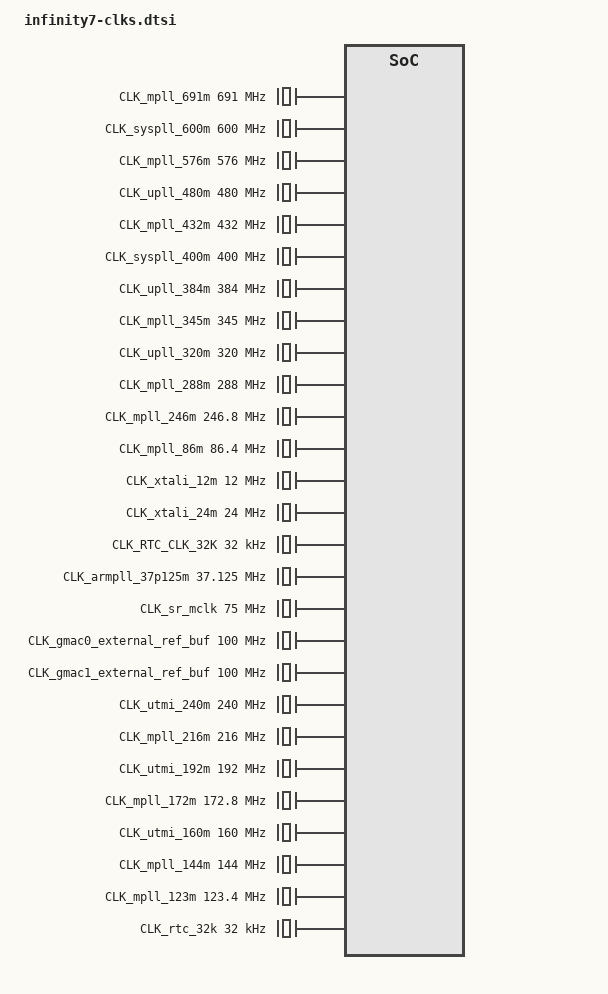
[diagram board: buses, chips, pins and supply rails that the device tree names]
/*
* infinity7-clks.dtsi- Sigmastar
*
* Copyright (c) [2019~2020] SigmaStar Technology.
*
*
* This software is licensed under the terms of the GNU General Public
* License version 2, as published by the Free Software Foundation, and
* may be copied, distributed, and modified under those terms.
*
* This program is distributed in the hope that it will be useful,
* but WITHOUT ANY WARRANTY; without even the implied warranty of
* MERCHANTABILITY or FITNESS FOR A PARTICULAR PURPOSE.  See the
* GNU General Public License version 2 for more details.
*
*/
/* generated by CLK_DT_GEN_5.2 */
/* CLK FILENAME: \\swfs01\Department2\training&Share\infinity7\Doc\04_Phase4\HW\Infinity7_Clock_Table_0214.xls */
/* REG FILENAME: I7\Infinity7_reg_CLKGEN.xls, I7\infinity7_reg_CLKGEN2.xls, I7\infinity7_reg_pm_sleep.xls, I7\Infinity7_reg_block.xls, I7\Infinity7_reg_chiptop.xls */

CLK_VOID: CLK_VOID {
    #clock-cells = <0>;
    compatible = "fixed-clock";
    clock-frequency = <1>;
};

CLK_mpll_691m: CLK_mpll_691m {
    #clock-cells = <0>;
    compatible = "fixed-clock";
    clock-frequency = <691000000>;
};

CLK_syspll_600m: CLK_syspll_600m {
    #clock-cells = <0>;
    compatible = "fixed-clock";
    clock-frequency = <600000000>;
};

CLK_mpll_576m: CLK_mpll_576m {
    #clock-cells = <0>;
    compatible = "fixed-clock";
    clock-frequency = <576000000>;
};

CLK_upll_480m: CLK_upll_480m {
    #clock-cells = <0>;
    compatible = "fixed-clock";
    clock-frequency = <480000000>;
};

CLK_mpll_432m: CLK_mpll_432m {
    #clock-cells = <0>;
    compatible = "fixed-clock";
    clock-frequency = <432000000>;
};

CLK_syspll_400m: CLK_syspll_400m {
    #clock-cells = <0>;
    compatible = "fixed-clock";
    clock-frequency = <400000000>;
};

CLK_upll_384m: CLK_upll_384m {
    #clock-cells = <0>;
    compatible = "fixed-clock";
    clock-frequency = <384000000>;
};

CLK_mpll_345m: CLK_mpll_345m {
    #clock-cells = <0>;
    compatible = "fixed-clock";
    clock-frequency = <345000000>;
};

CLK_upll_320m: CLK_upll_320m {
    #clock-cells = <0>;
    compatible = "fixed-clock";
    clock-frequency = <320000000>;
};

CLK_mpll_288m: CLK_mpll_288m {
    #clock-cells = <0>;
    compatible = "fixed-clock";
    clock-frequency = <288000000>;
};

CLK_mpll_246m: CLK_mpll_246m {
    #clock-cells = <0>;
    compatible = "fixed-clock";
    clock-frequency = <246800000>;
};

CLK_mpll_86m: CLK_mpll_86m {
    #clock-cells = <0>;
    compatible = "fixed-clock";
    clock-frequency = <86400000>;
};

CLK_upll_480m_div2: CLK_upll_480m_div2 {
    #clock-cells = <0>;
    compatible = "fixed-factor-clock";
    clocks = <&CLK_upll_480m>;
    clock-div = <2>;
    clock-mult = <1>;
};

CLK_upll_384m_div2: CLK_upll_384m_div2 {
    #clock-cells = <0>;
    compatible = "fixed-factor-clock";
    clocks = <&CLK_upll_384m>;
    clock-div = <2>;
    clock-mult = <1>;
};

CLK_mpll_345m_div2: CLK_mpll_345m_div2 {
    #clock-cells = <0>;
    compatible = "fixed-factor-clock";
    clocks = <&CLK_mpll_345m>;
    clock-div = <2>;
    clock-mult = <1>;
};

CLK_mpll_288m_div2: CLK_mpll_288m_div2 {
    #clock-cells = <0>;
    compatible = "fixed-factor-clock";
    clocks = <&CLK_mpll_288m>;
    clock-div = <2>;
    clock-mult = <1>;
};

CLK_mpll_288m_div4: CLK_mpll_288m_div4 {
    #clock-cells = <0>;
    compatible = "fixed-factor-clock";
    clocks = <&CLK_mpll_288m>;
    clock-div = <4>;
    clock-mult = <1>;
};

CLK_mpll_288m_div8: CLK_mpll_288m_div8 {
    #clock-cells = <0>;
    compatible = "fixed-factor-clock";
    clocks = <&CLK_mpll_288m>;
    clock-div = <8>;
    clock-mult = <1>;
};

CLK_mpll_432m_div2: CLK_mpll_432m_div2 {
    #clock-cells = <0>;
    compatible = "fixed-factor-clock";
    clocks = <&CLK_mpll_432m>;
    clock-div = <2>;
    clock-mult = <1>;
};

CLK_mpll_432m_div4: CLK_mpll_432m_div4 {
    #clock-cells = <0>;
    compatible = "fixed-factor-clock";
    clocks = <&CLK_mpll_432m>;
    clock-div = <4>;
    clock-mult = <1>;
};

CLK_mpll_432m_div8: CLK_mpll_432m_div8 {
    #clock-cells = <0>;
    compatible = "fixed-factor-clock";
    clocks = <&CLK_mpll_432m>;
    clock-div = <8>;
    clock-mult = <1>;
};

CLK_mpll_432m_div16: CLK_mpll_432m_div16 {
    #clock-cells = <0>;
    compatible = "fixed-factor-clock";
    clocks = <&CLK_mpll_432m>;
    clock-div = <16>;
    clock-mult = <1>;
};

CLK_mpll_246m_div2: CLK_mpll_246m_div2 {
    #clock-cells = <0>;
    compatible = "fixed-factor-clock";
    clocks = <&CLK_mpll_246m>;
    clock-div = <2>;
    clock-mult = <1>;
};

CLK_mpll_246m_div4: CLK_mpll_246m_div4 {
    #clock-cells = <0>;
    compatible = "fixed-factor-clock";
    clocks = <&CLK_mpll_246m>;
    clock-div = <4>;
    clock-mult = <1>;
};

CLK_mpll_86m_div2: CLK_mpll_86m_div2 {
    #clock-cells = <0>;
    compatible = "fixed-factor-clock";
    clocks = <&CLK_mpll_86m>;
    clock-div = <2>;
    clock-mult = <1>;
};

CLK_mpll_86m_div4: CLK_mpll_86m_div4 {
    #clock-cells = <0>;
    compatible = "fixed-factor-clock";
    clocks = <&CLK_mpll_86m>;
    clock-div = <4>;
    clock-mult = <1>;
};

CLK_mpll_86m_div16: CLK_mpll_86m_div16 {
    #clock-cells = <0>;
    compatible = "fixed-factor-clock";
    clocks = <&CLK_mpll_86m>;
    clock-div = <16>;
    clock-mult = <1>;
};

CLK_syspll_400m_div2: CLK_syspll_400m_div2 {
    #clock-cells = <0>;
    compatible = "fixed-factor-clock";
    clocks = <&CLK_syspll_400m>;
    clock-div = <2>;
    clock-mult = <1>;
};

CLK_syspll_400m_div4: CLK_syspll_400m_div4 {
    #clock-cells = <0>;
    compatible = "fixed-factor-clock";
    clocks = <&CLK_syspll_400m>;
    clock-div = <4>;
    clock-mult = <1>;
};

CLK_syspll_400m_div8: CLK_syspll_400m_div8 {
    #clock-cells = <0>;
    compatible = "fixed-factor-clock";
    clocks = <&CLK_syspll_400m>;
    clock-div = <8>;
    clock-mult = <1>;
};

CLK_upll_384m_div8: CLK_upll_384m_div8 {
    #clock-cells = <0>;
    compatible = "fixed-factor-clock";
    clocks = <&CLK_upll_384m>;
    clock-div = <8>;
    clock-mult = <1>;
};

CLK_upll_320m_div2: CLK_upll_320m_div2 {
    #clock-cells = <0>;
    compatible = "fixed-factor-clock";
    clocks = <&CLK_upll_320m>;
    clock-div = <2>;
    clock-mult = <1>;
};

CLK_upll_320m_div8: CLK_upll_320m_div8 {
    #clock-cells = <0>;
    compatible = "fixed-factor-clock";
    clocks = <&CLK_upll_320m>;
    clock-div = <8>;
    clock-mult = <1>;
};

CLK_upll_320m_div10: CLK_upll_320m_div10 {
    #clock-cells = <0>;
    compatible = "fixed-factor-clock";
    clocks = <&CLK_upll_320m>;
    clock-div = <10>;
    clock-mult = <1>;
};

CLK_upll_320m_div16: CLK_upll_320m_div16 {
    #clock-cells = <0>;
    compatible = "fixed-factor-clock";
    clocks = <&CLK_upll_320m>;
    clock-div = <16>;
    clock-mult = <1>;
};

CLK_xtali_12m: CLK_xtali_12m {
    #clock-cells = <0>;
    compatible = "fixed-clock";
    clock-frequency = <12000000>;
};

CLK_xtali_12m_div2: CLK_xtali_12m_div2 {
    #clock-cells = <0>;
    compatible = "fixed-factor-clock";
    clocks = <&CLK_xtali_12m>;
    clock-div = <2>;
    clock-mult = <1>;
};

CLK_xtali_12m_div4: CLK_xtali_12m_div4 {
    #clock-cells = <0>;
    compatible = "fixed-factor-clock";
    clocks = <&CLK_xtali_12m>;
    clock-div = <4>;
    clock-mult = <1>;
};

CLK_xtali_12m_div8: CLK_xtali_12m_div8 {
    #clock-cells = <0>;
    compatible = "fixed-factor-clock";
    clocks = <&CLK_xtali_12m>;
    clock-div = <8>;
    clock-mult = <1>;
};

CLK_xtali_12m_div16: CLK_xtali_12m_div16 {
    #clock-cells = <0>;
    compatible = "fixed-factor-clock";
    clocks = <&CLK_xtali_12m>;
    clock-div = <16>;
    clock-mult = <1>;
};

CLK_xtali_12m_div40: CLK_xtali_12m_div40 {
    #clock-cells = <0>;
    compatible = "fixed-factor-clock";
    clocks = <&CLK_xtali_12m>;
    clock-div = <40>;
    clock-mult = <1>;
};

CLK_xtali_12m_div64: CLK_xtali_12m_div64 {
    #clock-cells = <0>;
    compatible = "fixed-factor-clock";
    clocks = <&CLK_xtali_12m>;
    clock-div = <64>;
    clock-mult = <1>;
};

CLK_xtali_12m_div128: CLK_xtali_12m_div128 {
    #clock-cells = <0>;
    compatible = "fixed-factor-clock";
    clocks = <&CLK_xtali_12m>;
    clock-div = <128>;
    clock-mult = <1>;
};

CLK_xtali_24m: CLK_xtali_24m {
    #clock-cells = <0>;
    compatible = "fixed-clock";
    clock-frequency = <24000000>;
};

CLK_RTC_CLK_32K: CLK_RTC_CLK_32K {
    #clock-cells = <0>;
    compatible = "fixed-clock";
    clock-frequency = <32000>;
};

CLK_pm_riu_w_clk_in: CLK_pm_riu_w_clk_in {
    #clock-cells = <0>;
    compatible = "fixed-clock";
    clock-frequency = <108000000>;
};

CLK_gmacpll_250: CLK_gmacpll_250 {
    #clock-cells = <0>;
    compatible = "fixed-clock";
    clock-frequency = <250000000>;
};

CLK_gmacpll_250_div2: CLK_gmacpll_250_div2 {
    #clock-cells = <0>;
    compatible = "fixed-factor-clock";
    clocks = <&CLK_gmacpll_250>;
    clock-div = <2>;
    clock-mult = <1>;
};

CLK_gmacpll_250_div5: CLK_gmacpll_250_div5 {
    #clock-cells = <0>;
    compatible = "fixed-factor-clock";
    clocks = <&CLK_gmacpll_250>;
    clock-div = <5>;
    clock-mult = <1>;
};

CLK_gmacpll_250_div10: CLK_gmacpll_250_div10 {
    #clock-cells = <0>;
    compatible = "fixed-factor-clock";
    clocks = <&CLK_gmacpll_250>;
    clock-div = <10>;
    clock-mult = <1>;
};

CLK_gmacpll_250_div100: CLK_gmacpll_250_div100 {
    #clock-cells = <0>;
    compatible = "fixed-factor-clock";
    clocks = <&CLK_gmacpll_250>;
    clock-div = <100>;
    clock-mult = <1>;
};

CLK_isppll_clk: CLK_isppll_clk {
    #clock-cells = <0>;
    compatible = "fixed-clock";
    clock-frequency = <600000000>;
};

CLK_isppll_clk_div2: CLK_isppll_clk_div2 {
    #clock-cells = <0>;
    compatible = "fixed-factor-clock";
    clocks = <&CLK_isppll_clk>;
    clock-div = <2>;
    clock-mult = <1>;
};

CLK_isppll_clk_div4: CLK_isppll_clk_div4 {
    #clock-cells = <0>;
    compatible = "fixed-factor-clock";
    clocks = <&CLK_isppll_clk>;
    clock-div = <4>;
    clock-mult = <1>;
};

CLK_isppll_clk_div8: CLK_isppll_clk_div8 {
    #clock-cells = <0>;
    compatible = "fixed-factor-clock";
    clocks = <&CLK_isppll_clk>;
    clock-div = <8>;
    clock-mult = <1>;
};

CLK_isppll_clk_div16: CLK_isppll_clk_div16 {
    #clock-cells = <0>;
    compatible = "fixed-factor-clock";
    clocks = <&CLK_isppll_clk>;
    clock-div = <16>;
    clock-mult = <1>;
};

CLK_syspll_clk: CLK_syspll_clk {
    #clock-cells = <0>;
    compatible = "fixed-clock";
    clock-frequency = <600000000>;
};

CLK_spipll_clk: CLK_spipll_clk {
    #clock-cells = <0>;
    compatible = "fixed-clock";
    clock-frequency = <250000000>;
};

CLK_dsppll_clk: CLK_dsppll_clk {
    #clock-cells = <0>;
    compatible = "fixed-clock";
    clock-frequency = <1000000000>;
};

CLK_utmi: CLK_utmi {
    #clock-cells = <0>;
    compatible = "fixed-clock";
    clock-frequency = <60000000>;
};

CLK_ipupll_clk: CLK_ipupll_clk {
    #clock-cells = <0>;
    compatible = "fixed-clock";
    clock-frequency = <1000000000>;
};

CLK_miupll_clk: CLK_miupll_clk {
    #clock-cells = <0>;
    compatible = "fixed-clock";
    clock-frequency = <533000000>;
};

CLK_ddrpll_clk: CLK_ddrpll_clk {
    #clock-cells = <0>;
    compatible = "fixed-clock";
    clock-frequency = <2133000000>;
};

CLK_lpll_clk: CLK_lpll_clk {
    #clock-cells = <0>;
    compatible = "fixed-clock";
    clock-frequency = <600000000>;
};

CLK_disppll_clk: CLK_disppll_clk {
    #clock-cells = <0>;
    compatible = "fixed-clock";
    clock-frequency = <600000000>;
};

CLK_ven_pll: CLK_ven_pll {
    #clock-cells = <0>;
    compatible = "sstar,complex-clock";
    clocks = <&CLK_xtali_24m>;
};

CLK_ven_pll_div6: CLK_ven_pll_div6 {
    #clock-cells = <0>;
    compatible = "fixed-clock";
    clock-frequency = <100000000>;
};

CLK_cpu_pll: CLK_cpu_pll {
    #clock-cells = <0>;
    compatible = "fixed-clock";
    clock-frequency = <1000000000>;
};

CLK_lpll_clk_div2: CLK_lpll_clk_div2 {
    #clock-cells = <0>;
    compatible = "fixed-factor-clock";
    clocks = <&CLK_lpll_clk>;
    clock-div = <2>;
    clock-mult = <1>;
};

CLK_lpll_clk_div4: CLK_lpll_clk_div4 {
    #clock-cells = <0>;
    compatible = "fixed-factor-clock";
    clocks = <&CLK_lpll_clk>;
    clock-div = <4>;
    clock-mult = <1>;
};

CLK_lpll_clk_div8: CLK_lpll_clk_div8 {
    #clock-cells = <0>;
    compatible = "fixed-factor-clock";
    clocks = <&CLK_lpll_clk>;
    clock-div = <8>;
    clock-mult = <1>;
};

CLK_disppll_clk_div2: CLK_disppll_clk_div2 {
    #clock-cells = <0>;
    compatible = "fixed-factor-clock";
    clocks = <&CLK_disppll_clk>;
    clock-div = <2>;
    clock-mult = <1>;
};

CLK_disppll_clk_div4: CLK_disppll_clk_div4 {
    #clock-cells = <0>;
    compatible = "fixed-factor-clock";
    clocks = <&CLK_disppll_clk>;
    clock-div = <4>;
    clock-mult = <1>;
};

CLK_disppll_clk_div8: CLK_disppll_clk_div8 {
    #clock-cells = <0>;
    compatible = "fixed-factor-clock";
    clocks = <&CLK_disppll_clk>;
    clock-div = <8>;
    clock-mult = <1>;
};

CLK_armpll_37p125m: CLK_armpll_37p125m {
    #clock-cells = <0>;
    compatible = "fixed-clock";
    clock-frequency = <37125000>;
};

CLK_riu_w_clk_in: CLK_riu_w_clk_in {
    #clock-cells = <0>;
    compatible = "fixed-factor-clock";
    clocks = <&CLK_mcu>;
    clock-div = <1>;
    clock-mult = <1>;
};

CLK_riu_w_clk_top: CLK_riu_w_clk_top {
    #clock-cells = <0>;
    compatible = "fixed-factor-clock";
    clocks = <&CLK_mcu>;
    clock-div = <1>;
    clock-mult = <1>;
};

CLK_riu_w_clk_sc_gp: CLK_riu_w_clk_sc_gp {
    #clock-cells = <0>;
    compatible = "fixed-factor-clock";
    clocks = <&CLK_mcu>;
    clock-div = <1>;
    clock-mult = <1>;
};

CLK_riu_w_clk_vhe_gp: CLK_riu_w_clk_vhe_gp {
    #clock-cells = <0>;
    compatible = "fixed-factor-clock";
    clocks = <&CLK_mcu>;
    clock-div = <1>;
    clock-mult = <1>;
};

CLK_riu_w_clk_hemcu_gp: CLK_riu_w_clk_hemcu_gp {
    #clock-cells = <0>;
    compatible = "fixed-factor-clock";
    clocks = <&CLK_mcu>;
    clock-div = <1>;
    clock-mult = <1>;
};

CLK_riu_w_clk_mipi_if_gp: CLK_riu_w_clk_mipi_if_gp {
    #clock-cells = <0>;
    compatible = "fixed-factor-clock";
    clocks = <&CLK_mcu>;
    clock-div = <1>;
    clock-mult = <1>;
};

CLK_riu_w_clk_mcu_if_gp: CLK_riu_w_clk_mcu_if_gp {
    #clock-cells = <0>;
    compatible = "fixed-factor-clock";
    clocks = <&CLK_mcu>;
    clock-div = <1>;
    clock-mult = <1>;
};

CLK_spi_synth_pll: CLK_spi_synth_pll {
    #clock-cells = <0>;
    compatible = "fixed-clock";
    clock-frequency = <104000000>;
};

CLK_fuart0_synth_out: CLK_fuart0_synth_out {
    #clock-cells = <0>;
    compatible = "sstar,complex-clock";
    clocks = <&CLK_fuart0_synth_in>;

};

CLK_miu: CLK_miu {
    #clock-cells = <0>;
    compatible = "fixed-clock";
    clock-frequency = <400000000>;
};

CLK_miu_p: CLK_miu_p {
    #clock-cells = <0>;
    compatible = "fixed-factor-clock";
    clocks = <&CLK_miu>;
    clock-div = <1>;
    clock-mult = <1>;
};

CLK_mspi0_p: CLK_mspi0_p {
    #clock-cells = <0>;
    compatible = "fixed-factor-clock";
    clocks = <&CLK_mspi0>;
    clock-div = <1>;
    clock-mult = <1>;
};

CLK_mspi1_p: CLK_mspi1_p {
    #clock-cells = <0>;
    compatible = "fixed-factor-clock";
    clocks = <&CLK_mspi1>;
    clock-div = <1>;
    clock-mult = <1>;
};

CLK_miu_vhe_gp_p: CLK_miu_vhe_gp_p {
    #clock-cells = <0>;
    compatible = "fixed-factor-clock";
    clocks = <&CLK_miu>;
    clock-div = <1>;
    clock-mult = <1>;
};

CLK_miu_sc_gp_p: CLK_miu_sc_gp_p {
    #clock-cells = <0>;
    compatible = "fixed-factor-clock";
    clocks = <&CLK_miu>;
    clock-div = <1>;
    clock-mult = <1>;
};

CLK_miu_isp_gp_p: CLK_miu_isp_gp_p {
    #clock-cells = <0>;
    compatible = "fixed-factor-clock";
    clocks = <&CLK_miu>;
    clock-div = <1>;
    clock-mult = <1>;
};

CLK_miu2x_p: CLK_miu2x_p {
    #clock-cells = <0>;
    compatible = "fixed-factor-clock";
    clocks = <&CLK_miu>;
    clock-div = <1>;
    clock-mult = <1>;
};

CLK_mcu_p: CLK_mcu_p {
    #clock-cells = <0>;
    compatible = "fixed-factor-clock";
    clocks = <&CLK_mcu>;
    clock-div = <1>;
    clock-mult = <1>;
};

CLK_mcu_pm_p: CLK_mcu_pm_p {
    #clock-cells = <0>;
    compatible = "fixed-factor-clock";
    clocks = <&CLK_mcu_pm>;
    clock-div = <1>;
    clock-mult = <1>;
};

CLK_isp_p: CLK_isp_p {
    #clock-cells = <0>;
    compatible = "fixed-factor-clock";
    clocks = <&CLK_isp>;
    clock-div = <1>;
    clock-mult = <1>;
};

CLK_fclk1_p: CLK_fclk1_p {
    #clock-cells = <0>;
    compatible = "fixed-factor-clock";
    clocks = <&CLK_fclk1>;
    clock-div = <1>;
    clock-mult = <1>;
};

CLK_sdio_p: CLK_sdio_p {
    #clock-cells = <0>;
    compatible = "fixed-factor-clock";
    clocks = <&CLK_sdio>;
    clock-div = <1>;
    clock-mult = <1>;
};

CLK_sd_1x_p: CLK_sd_1x_p {
    #clock-cells = <0>;
    compatible = "fixed-clock";
    clock-frequency = <110000000>;
};

CLK_sd_2x_p: CLK_sd_2x_p {
    #clock-cells = <0>;
    compatible = "fixed-clock";
    clock-frequency = <220000000>;
};

CLK_sr_mclk: CLK_sr_mclk {
    #clock-cells = <0>;
    compatible = "fixed-clock";
    clock-frequency = <75000000>;
};

CLK_tck_buf: CLK_tck_buf {
    #clock-cells = <0>;
    compatible = "fixed-clock";
    clock-frequency = <50000000>;
};

CLK_eth_buf: CLK_eth_buf {
    #clock-cells = <0>;
    compatible = "fixed-clock";
    clock-frequency = <125000000>;
};

CLK_rmii_buf: CLK_rmii_buf {
    #clock-cells = <0>;
    compatible = "fixed-clock";
    clock-frequency = <125000000>;
};

CLK_emac_testrx125_in_lan: CLK_emac_testrx125_in_lan {
    #clock-cells = <0>;
    compatible = "fixed-clock";
    clock-frequency = <125000000>;
};

CLK_gmac0_external_ref_buf: CLK_gmac0_external_ref_buf {
    #clock-cells = <0>;
    compatible = "fixed-clock";
    clock-frequency = <100000000>;
};

CLK_gmac1_external_ref_buf: CLK_gmac1_external_ref_buf {
    #clock-cells = <0>;
    compatible = "fixed-clock";
    clock-frequency = <100000000>;
};

CLK_utmi_240m: CLK_utmi_240m {
    #clock-cells = <0>;
    compatible = "fixed-clock";
    clock-frequency = <240000000>;
};

CLK_mpll_216m: CLK_mpll_216m {
    #clock-cells = <0>;
    compatible = "fixed-clock";
    clock-frequency = <216000000>;
};

CLK_utmi_192m: CLK_utmi_192m {
    #clock-cells = <0>;
    compatible = "fixed-clock";
    clock-frequency = <192000000>;
};

CLK_mpll_172m: CLK_mpll_172m {
    #clock-cells = <0>;
    compatible = "fixed-clock";
    clock-frequency = <172800000>;
};

CLK_utmi_160m: CLK_utmi_160m {
    #clock-cells = <0>;
    compatible = "fixed-clock";
    clock-frequency = <160000000>;
};

CLK_mpll_144m: CLK_mpll_144m {
    #clock-cells = <0>;
    compatible = "fixed-clock";
    clock-frequency = <144000000>;
};

CLK_mpll_123m: CLK_mpll_123m {
    #clock-cells = <0>;
    compatible = "fixed-clock";
    clock-frequency = <123400000>;
};

CLK_mpll_216m_div2: CLK_mpll_216m_div2 {
    #clock-cells = <0>;
    compatible = "fixed-factor-clock";
    clocks = <&CLK_mpll_216m>;
    clock-div = <2>;
    clock-mult = <1>;
};

CLK_mpll_216m_div4: CLK_mpll_216m_div4 {
    #clock-cells = <0>;
    compatible = "fixed-factor-clock";
    clocks = <&CLK_mpll_216m>;
    clock-div = <4>;
    clock-mult = <1>;
};

CLK_mpll_216m_div8: CLK_mpll_216m_div8 {
    #clock-cells = <0>;
    compatible = "fixed-factor-clock";
    clocks = <&CLK_mpll_216m>;
    clock-div = <8>;
    clock-mult = <1>;
};

CLK_mpll_144m_div2: CLK_mpll_144m_div2 {
    #clock-cells = <0>;
    compatible = "fixed-factor-clock";
    clocks = <&CLK_mpll_144m>;
    clock-div = <2>;
    clock-mult = <1>;
};

CLK_mpll_144m_div4: CLK_mpll_144m_div4 {
    #clock-cells = <0>;
    compatible = "fixed-factor-clock";
    clocks = <&CLK_mpll_144m>;
    clock-div = <4>;
    clock-mult = <1>;
};

CLK_mpll_123m_div2: CLK_mpll_123m_div2 {
    #clock-cells = <0>;
    compatible = "fixed-factor-clock";
    clocks = <&CLK_mpll_123m>;
    clock-div = <2>;
    clock-mult = <1>;
};

CLK_utmi_192m_div4: CLK_utmi_192m_div4 {
    #clock-cells = <0>;
    compatible = "fixed-factor-clock";
    clocks = <&CLK_utmi_192m>;
    clock-div = <4>;
    clock-mult = <1>;
};

CLK_utmi_160m_div4: CLK_utmi_160m_div4 {
    #clock-cells = <0>;
    compatible = "fixed-factor-clock";
    clocks = <&CLK_utmi_160m>;
    clock-div = <4>;
    clock-mult = <1>;
};

CLK_utmi_160m_div5: CLK_utmi_160m_div5 {
    #clock-cells = <0>;
    compatible = "fixed-factor-clock";
    clocks = <&CLK_utmi_160m>;
    clock-div = <5>;
    clock-mult = <1>;
};

CLK_utmi_160m_div8: CLK_utmi_160m_div8 {
    #clock-cells = <0>;
    compatible = "fixed-factor-clock";
    clocks = <&CLK_utmi_160m>;
    clock-div = <8>;
    clock-mult = <1>;
};

CLK_xtali_12m_div12: CLK_xtali_12m_div12 {
    #clock-cells = <0>;
    compatible = "fixed-factor-clock";
    clocks = <&CLK_xtali_12m>;
    clock-div = <12>;
    clock-mult = <1>;
};

CLK_rtc_32k: CLK_rtc_32k {
    #clock-cells = <0>;
    compatible = "fixed-clock";
    clock-frequency = <32000>;
};

CLK_rtc_32k_div4: CLK_rtc_32k_div4 {
    #clock-cells = <0>;
    compatible = "fixed-factor-clock";
    clocks = <&CLK_rtc_32k>;
    clock-div = <4>;
    clock-mult = <1>;
};

CLK_cpupll_clk: CLK_cpupll_clk {
    #clock-cells = <0>;
    compatible = "sstar,complex-clock";
    clocks = <&CLK_mpll_432m>;
};

CLK_SPI_SYNTH_CLK_OUT_buf: CLK_SPI_SYNTH_CLK_OUT_buf {
    #clock-cells = <0>;
    compatible = "fixed-clock";
    clock-frequency = <104000000>;
};

CLK_live_pm: CLK_live_pm {
    #clock-cells = <0>;
    compatible = "fixed-factor-clock";
    clocks = <&CLK_xtali_12m>;
    clock-div = <1>;
    clock-mult = <1>;
};

CLK_riu_pm: CLK_riu_pm {
    #clock-cells = <0>;
    compatible = "fixed-factor-clock";
    clocks = <&CLK_pm_riu_w_clk_in>;
    clock-div = <1>;
    clock-mult = <1>;
};

CLK_ddr_syn: CLK_ddr_syn {
    #clock-cells = <0>;
    compatible = "sstar,composite-clock";
    clocks = <&CLK_mpll_432m>,<&CLK_mpll_432m_div2>,<&CLK_xtali_12m>,<&CLK_VOID>;
    reg = <REG_CKG_DDR_SYN_BASE 0x4>;
    mux-shift = <2>;  //2+REG_CKG_DDR_SYN_OFFSET
    mux-width = <2>;
    gate-shift = <0>;  //0+REG_CKG_DDR_SYN_OFFSET
    auto-enable = <1>;
};

CLK_miu_rec: CLK_miu_rec {
    #clock-cells = <0>;
    compatible = "sstar,composite-clock";
    clocks = <&CLK_xtali_12m_div8>,<&CLK_xtali_12m_div16>,<&CLK_xtali_12m_div64>,<&CLK_xtali_12m_div128>;
    reg = <REG_CKG_MIU_REC_BASE 0x4>;
    mux-shift = <2>;  //2+REG_CKG_MIU_REC_OFFSET
    mux-width = <2>;
    gate-shift = <0>;  //0+REG_CKG_MIU_REC_OFFSET
    auto-enable = <1>;
};

CLK_mcu: CLK_mcu {
    #clock-cells = <0>;
    compatible = "sstar,composite-clock";
    clocks = <&CLK_mpll_432m_div2>,<&CLK_mpll_432m>,<&CLK_upll_320m>,<&CLK_mpll_345m>,<&CLK_upll_384m>,<&CLK_mpll_288m>,<&CLK_mpll_345m_div2>,<&CLK_mpll_432m_div4>;
    reg = <REG_CKG_MCU_BASE 0x4>;
    mux-shift = <2>;  //2+REG_CKG_MCU_OFFSET
    mux-width = <3>;
    gate-shift = <0>;  //0+REG_CKG_MCU_OFFSET
    glitch-shift = <5>;  //5+REG_CKG_MCU_OFFSET
    auto-enable = <1>;
};

CLK_riubrdg: CLK_riubrdg {
    #clock-cells = <0>;
    compatible = "sstar,composite-clock";
    clocks = <&CLK_mcu_p>,<&CLK_VOID>,<&CLK_VOID>,<&CLK_VOID>;
    reg = <REG_CKG_RIUBRDG_BASE 0x4>;
    mux-shift = <10>;  //2+REG_CKG_RIUBRDG_OFFSET
    mux-width = <2>;
    gate-shift = <8>;  //0+REG_CKG_RIUBRDG_OFFSET
    auto-enable = <1>;
};

CLK_spi_arb: CLK_spi_arb {
    #clock-cells = <0>;
    compatible = "sstar,composite-clock";
    clocks = <&CLK_miu_p>,<&CLK_VOID>,<&CLK_VOID>,<&CLK_VOID>;
    reg = <REG_CKG_SPI_ARB_BASE 0x4>;
    mux-shift = <2>;  //2+REG_CKG_SPI_ARB_OFFSET
    mux-width = <2>;
    gate-shift = <0>;  //0+REG_CKG_SPI_ARB_OFFSET
    glitch-shift = <4>;  //4+REG_CKG_SPI_ARB_OFFSET
    auto-enable = <0>;
};

CLK_pwm: CLK_pwm {
    #clock-cells = <0>;
    compatible = "sstar,composite-clock";
    clocks = <&CLK_xtali_12m>,<&CLK_xtali_12m_div2>,<&CLK_xtali_12m_div4>,<&CLK_xtali_12m_div8>,<&CLK_xtali_12m_div16>,<&CLK_mpll_86m>,<&CLK_VOID>,<&CLK_VOID>;
    reg = <REG_CKG_PWM_BASE 0x4>;
    mux-shift = <10>;  //2+REG_CKG_PWM_OFFSET
    mux-width = <3>;
    gate-shift = <8>;  //0+REG_CKG_PWM_OFFSET
    auto-enable = <0>;
};

CLK_uart0: CLK_uart0 {
    #clock-cells = <0>;
    compatible = "sstar,composite-clock";
    clocks = <&CLK_mpll_345m_div2>,<&CLK_mpll_288m_div2>,<&CLK_xtali_24m>,<&CLK_xtali_12m>;
    reg = <REG_CKG_UART0_BASE 0x4>;
    mux-shift = <2>;  //2+REG_CKG_UART0_OFFSET
    mux-width = <2>;
    gate-shift = <0>;  //0+REG_CKG_UART0_OFFSET
    auto-enable = <1>;
};

CLK_uart1: CLK_uart1 {
    #clock-cells = <0>;
    compatible = "sstar,composite-clock";
    clocks = <&CLK_mpll_345m_div2>,<&CLK_mpll_288m_div2>,<&CLK_xtali_24m>,<&CLK_xtali_12m>;
    reg = <REG_CKG_UART1_BASE 0x4>;
    mux-shift = <6>;  //2+REG_CKG_UART1_OFFSET
    mux-width = <2>;
    gate-shift = <4>;  //0+REG_CKG_UART1_OFFSET
    auto-enable = <0>;
};

CLK_uart2: CLK_uart2 {
    #clock-cells = <0>;
    compatible = "sstar,composite-clock";
    clocks = <&CLK_mpll_345m_div2>,<&CLK_mpll_288m_div2>,<&CLK_xtali_24m>,<&CLK_xtali_12m>;
    reg = <REG_CKG_UART2_BASE 0x4>;
    mux-shift = <10>;  //2+REG_CKG_UART2_OFFSET
    mux-width = <2>;
    gate-shift = <8>;  //0+REG_CKG_UART2_OFFSET
    auto-enable = <0>;
};

CLK_uart3: CLK_uart3 {
    #clock-cells = <0>;
    compatible = "sstar,composite-clock";
    clocks = <&CLK_mpll_345m_div2>,<&CLK_mpll_288m_div2>,<&CLK_xtali_24m>,<&CLK_xtali_12m>;
    reg = <REG_CKG_UART3_BASE 0x4>;
    mux-shift = <14>;  //2+REG_CKG_UART3_OFFSET
    mux-width = <2>;
    gate-shift = <12>;  //0+REG_CKG_UART3_OFFSET
    auto-enable = <0>;
};

CLK_uart4: CLK_uart4 {
    #clock-cells = <0>;
    compatible = "sstar,composite-clock";
    clocks = <&CLK_mpll_345m_div2>,<&CLK_mpll_288m_div2>,<&CLK_xtali_24m>,<&CLK_xtali_12m>;
    reg = <REG_CKG_UART4_BASE 0x4>;
    mux-shift = <2>;  //2+REG_CKG_UART4_OFFSET
    mux-width = <2>;
    gate-shift = <0>;  //0+REG_CKG_UART4_OFFSET
    auto-enable = <0>;
};

CLK_uart5: CLK_uart5 {
    #clock-cells = <0>;
    compatible = "sstar,composite-clock";
    clocks = <&CLK_mpll_345m_div2>,<&CLK_mpll_288m_div2>,<&CLK_xtali_24m>,<&CLK_xtali_12m>;
    reg = <REG_CKG_UART5_BASE 0x4>;
    mux-shift = <2>;  //2+REG_CKG_UART5_OFFSET
    mux-width = <2>;
    gate-shift = <0>;  //0+REG_CKG_UART5_OFFSET
    auto-enable = <0>;
};

CLK_fuart0_synth_in: CLK_fuart0_synth_in {
    #clock-cells = <0>;
    compatible = "sstar,composite-clock";
    clocks = <&CLK_mpll_432m>,<&CLK_mpll_432m_div2>,<&CLK_VOID>,<&CLK_VOID>;
    reg = <REG_CKG_FUART0_SYNTH_IN_BASE 0x4>;
    mux-shift = <6>;  //2+REG_CKG_FUART0_SYNTH_IN_OFFSET
    mux-width = <2>;
    gate-shift = <4>;  //0+REG_CKG_FUART0_SYNTH_IN_OFFSET
    auto-enable = <0>;
};

CLK_fuart: CLK_fuart {
    #clock-cells = <0>;
    compatible = "sstar,composite-clock";
    clocks = <&CLK_mpll_345m_div2>,<&CLK_mpll_288m_div2>,<&CLK_xtali_12m>,<&CLK_fuart0_synth_out>;
    reg = <REG_CKG_FUART_BASE 0x4>;
    mux-shift = <2>;  //2+REG_CKG_FUART_OFFSET
    mux-width = <2>;
    gate-shift = <0>;  //0+REG_CKG_FUART_OFFSET
    auto-enable = <0>;
};

CLK_mspi0: CLK_mspi0 {
    #clock-cells = <0>;
    compatible = "sstar,composite-clock";
    clocks = <&CLK_mpll_432m_div4>,<&CLK_mpll_432m_div8>,<&CLK_xtali_12m>,<&CLK_mpll_288m_div2>;
    reg = <REG_CKG_MSPI0_BASE 0x4>;
    mux-shift = <2>;  //2+REG_CKG_MSPI0_OFFSET
    mux-width = <2>;
    gate-shift = <0>;  //0+REG_CKG_MSPI0_OFFSET
    auto-enable = <0>;
};

CLK_mspi1: CLK_mspi1 {
    #clock-cells = <0>;
    compatible = "sstar,composite-clock";
    clocks = <&CLK_mpll_432m_div4>,<&CLK_mpll_432m_div8>,<&CLK_xtali_12m>,<&CLK_mpll_288m_div2>;
    reg = <REG_CKG_MSPI1_BASE 0x4>;
    mux-shift = <10>;  //2+REG_CKG_MSPI1_OFFSET
    mux-width = <2>;
    gate-shift = <8>;  //0+REG_CKG_MSPI1_OFFSET
    auto-enable = <0>;
};

CLK_mspi2: CLK_mspi2 {
    #clock-cells = <0>;
    compatible = "sstar,composite-clock";
    clocks = <&CLK_mpll_432m_div4>,<&CLK_mpll_432m_div8>,<&CLK_xtali_12m>,<&CLK_mpll_288m_div2>;
    reg = <REG_CKG_MSPI2_BASE 0x4>;
    mux-shift = <10>;  //2+REG_CKG_MSPI2_OFFSET
    mux-width = <2>;
    gate-shift = <8>;  //0+REG_CKG_MSPI2_OFFSET
    auto-enable = <0>;
};

CLK_mspi3: CLK_mspi3 {
    #clock-cells = <0>;
    compatible = "sstar,composite-clock";
    clocks = <&CLK_mpll_432m_div4>,<&CLK_mpll_432m_div8>,<&CLK_xtali_12m>,<&CLK_mpll_288m_div2>;
    reg = <REG_CKG_MSPI3_BASE 0x4>;
    mux-shift = <14>;  //2+REG_CKG_MSPI3_OFFSET
    mux-width = <2>;
    gate-shift = <12>;  //0+REG_CKG_MSPI3_OFFSET
    auto-enable = <0>;
};

CLK_miic0: CLK_miic0 {
    #clock-cells = <0>;
    compatible = "sstar,composite-clock";
    clocks = <&CLK_mpll_288m_div4>,<&CLK_mpll_432m_div8>,<&CLK_xtali_12m>,<&CLK_VOID>;
    reg = <REG_CKG_MIIC0_BASE 0x4>;
    mux-shift = <2>;  //2+REG_CKG_MIIC0_OFFSET
    mux-width = <2>;
    gate-shift = <0>;  //0+REG_CKG_MIIC0_OFFSET
    auto-enable = <0>;
};

CLK_miic1: CLK_miic1 {
    #clock-cells = <0>;
    compatible = "sstar,composite-clock";
    clocks = <&CLK_mpll_288m_div4>,<&CLK_mpll_432m_div8>,<&CLK_xtali_12m>,<&CLK_VOID>;
    reg = <REG_CKG_MIIC1_BASE 0x4>;
    mux-shift = <10>;  //2+REG_CKG_MIIC1_OFFSET
    mux-width = <2>;
    gate-shift = <8>;  //0+REG_CKG_MIIC1_OFFSET
    auto-enable = <0>;
};

CLK_miic2: CLK_miic2 {
    #clock-cells = <0>;
    compatible = "sstar,composite-clock";
    clocks = <&CLK_mpll_288m_div4>,<&CLK_mpll_432m_div8>,<&CLK_xtali_12m>,<&CLK_VOID>;
    reg = <REG_CKG_MIIC2_BASE 0x4>;
    mux-shift = <14>;  //2+REG_CKG_MIIC2_OFFSET
    mux-width = <2>;
    gate-shift = <12>;  //0+REG_CKG_MIIC2_OFFSET
    auto-enable = <0>;
};

CLK_miic3: CLK_miic3 {
    #clock-cells = <0>;
    compatible = "sstar,composite-clock";
    clocks = <&CLK_mpll_288m_div4>,<&CLK_mpll_432m_div8>,<&CLK_xtali_12m>,<&CLK_VOID>;
    reg = <REG_CKG_MIIC3_BASE 0x4>;
    mux-shift = <2>;  //2+REG_CKG_MIIC3_OFFSET
    mux-width = <2>;
    gate-shift = <0>;  //0+REG_CKG_MIIC3_OFFSET
    auto-enable = <0>;
};

CLK_miic4: CLK_miic4 {
    #clock-cells = <0>;
    compatible = "sstar,composite-clock";
    clocks = <&CLK_mpll_288m_div4>,<&CLK_mpll_432m_div8>,<&CLK_xtali_12m>,<&CLK_VOID>;
    reg = <REG_CKG_MIIC4_BASE 0x4>;
    mux-shift = <10>;  //2+REG_CKG_MIIC4_OFFSET
    mux-width = <2>;
    gate-shift = <8>;  //0+REG_CKG_MIIC4_OFFSET
    auto-enable = <0>;
};

CLK_miic5: CLK_miic5 {
    #clock-cells = <0>;
    compatible = "sstar,composite-clock";
    clocks = <&CLK_mpll_288m_div4>,<&CLK_mpll_432m_div8>,<&CLK_xtali_12m>,<&CLK_VOID>;
    reg = <REG_CKG_MIIC5_BASE 0x4>;
    mux-shift = <14>;  //2+REG_CKG_MIIC5_OFFSET
    mux-width = <2>;
    gate-shift = <12>;  //0+REG_CKG_MIIC5_OFFSET
    auto-enable = <0>;
};

CLK_miic6: CLK_miic6 {
    #clock-cells = <0>;
    compatible = "sstar,composite-clock";
    clocks = <&CLK_mpll_288m_div4>,<&CLK_mpll_432m_div8>,<&CLK_xtali_12m>,<&CLK_VOID>;
    reg = <REG_CKG_MIIC6_BASE 0x4>;
    mux-shift = <2>;  //2+REG_CKG_MIIC6_OFFSET
    mux-width = <2>;
    gate-shift = <0>;  //0+REG_CKG_MIIC6_OFFSET
    auto-enable = <0>;
};

CLK_miic7: CLK_miic7 {
    #clock-cells = <0>;
    compatible = "sstar,composite-clock";
    clocks = <&CLK_mpll_288m_div4>,<&CLK_mpll_432m_div8>,<&CLK_xtali_12m>,<&CLK_VOID>;
    reg = <REG_CKG_MIIC7_BASE 0x4>;
    mux-shift = <2>;  //2+REG_CKG_MIIC7_OFFSET
    mux-width = <2>;
    gate-shift = <0>;  //0+REG_CKG_MIIC7_OFFSET
    auto-enable = <0>;
};

CLK_miic8: CLK_miic8 {
    #clock-cells = <0>;
    compatible = "sstar,composite-clock";
    clocks = <&CLK_mpll_288m_div4>,<&CLK_mpll_432m_div8>,<&CLK_xtali_12m>,<&CLK_VOID>;
    reg = <REG_CKG_MIIC8_BASE 0x4>;
    mux-shift = <2>;  //2+REG_CKG_MIIC8_OFFSET
    mux-width = <2>;
    gate-shift = <0>;  //0+REG_CKG_MIIC8_OFFSET
    auto-enable = <0>;
};

CLK_miic9: CLK_miic9 {
    #clock-cells = <0>;
    compatible = "sstar,composite-clock";
    clocks = <&CLK_mpll_288m_div4>,<&CLK_mpll_432m_div8>,<&CLK_xtali_12m>,<&CLK_VOID>;
    reg = <REG_CKG_MIIC9_BASE 0x4>;
    mux-shift = <2>;  //2+REG_CKG_MIIC9_OFFSET
    mux-width = <2>;
    gate-shift = <0>;  //0+REG_CKG_MIIC9_OFFSET
    auto-enable = <0>;
};

CLK_miic10: CLK_miic10 {
    #clock-cells = <0>;
    compatible = "sstar,composite-clock";
    clocks = <&CLK_mpll_288m_div4>,<&CLK_mpll_432m_div8>,<&CLK_xtali_12m>,<&CLK_VOID>;
    reg = <REG_CKG_MIIC10_BASE 0x4>;
    mux-shift = <2>;  //2+REG_CKG_MIIC10_OFFSET
    mux-width = <2>;
    gate-shift = <0>;  //0+REG_CKG_MIIC10_OFFSET
    auto-enable = <0>;
};

CLK_bist: CLK_bist {
    #clock-cells = <0>;
    compatible = "sstar,composite-clock";
    clocks = <&CLK_upll_320m>,<&CLK_mpll_288m>,<&CLK_upll_480m_div2>,<&CLK_mpll_432m_div2>,<&CLK_mpll_345m_div2>,<&CLK_mpll_288m_div2>,<&CLK_mpll_432m_div8>,<&CLK_xtali_12m>;
    reg = <REG_CKG_BIST_BASE 0x4>;
    mux-shift = <2>;  //2+REG_CKG_BIST_OFFSET
    mux-width = <3>;
    gate-shift = <0>;  //0+REG_CKG_BIST_OFFSET
    auto-enable = <0>;
};

CLK_bist_mcu: CLK_bist_mcu {
    #clock-cells = <0>;
    compatible = "sstar,composite-clock";
    clocks = <&CLK_upll_320m>,<&CLK_mpll_288m>,<&CLK_upll_480m_div2>,<&CLK_mpll_432m_div2>,<&CLK_mpll_345m_div2>,<&CLK_mpll_288m_div2>,<&CLK_mpll_432m_div8>,<&CLK_xtali_12m>;
    reg = <REG_CKG_BIST_MCU_BASE 0x4>;
    mux-shift = <2>;  //2+REG_CKG_BIST_MCU_OFFSET
    mux-width = <3>;
    gate-shift = <0>;  //0+REG_CKG_BIST_MCU_OFFSET
    auto-enable = <0>;
};

CLK_pwr_ctl: CLK_pwr_ctl {
    #clock-cells = <0>;
    compatible = "sstar,composite-clock";
    clocks = <&CLK_xtali_12m_div16>,<&CLK_xtali_12m_div8>,<&CLK_xtali_12m>,<&CLK_VOID>;
    reg = <REG_CKG_PWR_CTL_BASE 0x4>;
    mux-shift = <2>;  //2+REG_CKG_PWR_CTL_OFFSET
    mux-width = <2>;
    gate-shift = <0>;  //0+REG_CKG_PWR_CTL_OFFSET
    auto-enable = <0>;
};

CLK_xtali: CLK_xtali {
    #clock-cells = <0>;
    compatible = "sstar,composite-clock";
    clocks = <&CLK_xtali_12m>,<&CLK_VOID>,<&CLK_VOID>,<&CLK_VOID>;
    reg = <REG_CKG_XTALI_BASE 0x4>;
    mux-shift = <2>;  //2+REG_CKG_XTALI_OFFSET
    mux-width = <2>;
    gate-shift = <0>;  //0+REG_CKG_XTALI_OFFSET
    auto-enable = <1>;
};

CLK_live_c: CLK_live_c {
    #clock-cells = <0>;
    compatible = "sstar,composite-clock";
    clocks = <&CLK_xtali_12m>,<&CLK_VOID>,<&CLK_VOID>,<&CLK_VOID>;
    reg = <REG_CKG_LIVE_BASE 0x4>;
    mux-shift = <10>;  //2+REG_CKG_LIVE_OFFSET
    mux-width = <2>;
    gate-shift = <8>;  //0+REG_CKG_LIVE_OFFSET
    auto-enable = <1>;
};

CLK_live: CLK_live {
    #clock-cells = <0>;
    compatible = "sstar,composite-clock";
    clocks = <&CLK_xtali_12m>,<&CLK_VOID>,<&CLK_VOID>,<&CLK_VOID>;
    reg = <REG_CKG_LIVE_BASE 0x4>;
    mux-shift = <10>;  //2+REG_CKG_LIVE_OFFSET
    mux-width = <2>;
    gate-shift = <8>;  //0+REG_CKG_LIVE_OFFSET
    auto-enable = <1>;
};

CLK_sr00_mclk: CLK_sr00_mclk {
    #clock-cells = <0>;
    compatible = "sstar,composite-clock";
    clocks = <&CLK_mpll_432m_div16>,<&CLK_mpll_288m_div4>,<&CLK_mpll_246m_div4>,<&CLK_mpll_432m_div8>,<&CLK_upll_384m_div8>,<&CLK_mpll_86m_div2>,<&CLK_mpll_288m_div8>,<&CLK_xtali_24m>,<&CLK_mpll_86m_div4>,<&CLK_xtali_12m>,<&CLK_mpll_86m_div16>,<&CLK_isppll_clk_div2>,<&CLK_isppll_clk_div4>,<&CLK_isppll_clk_div8>,<&CLK_isppll_clk_div16>,<&CLK_VOID>;
    reg = <REG_CKG_SR00_MCLK_BASE 0x4>;
    mux-shift = <10>;  //2+REG_CKG_SR00_MCLK_OFFSET
    mux-width = <4>;
    gate-shift = <8>;  //0+REG_CKG_SR00_MCLK_OFFSET
    auto-enable = <0>;
};

CLK_sr01_mclk: CLK_sr01_mclk {
    #clock-cells = <0>;
    compatible = "sstar,composite-clock";
    clocks = <&CLK_mpll_432m_div16>,<&CLK_mpll_288m_div4>,<&CLK_mpll_246m_div4>,<&CLK_mpll_432m_div8>,<&CLK_upll_384m_div8>,<&CLK_mpll_86m_div2>,<&CLK_mpll_288m_div8>,<&CLK_xtali_24m>,<&CLK_mpll_86m_div4>,<&CLK_xtali_12m>,<&CLK_mpll_86m_div16>,<&CLK_isppll_clk_div2>,<&CLK_isppll_clk_div4>,<&CLK_isppll_clk_div8>,<&CLK_isppll_clk_div16>,<&CLK_VOID>;
    reg = <REG_CKG_SR01_MCLK_BASE 0x4>;
    mux-shift = <2>;  //2+REG_CKG_SR01_MCLK_OFFSET
    mux-width = <4>;
    gate-shift = <0>;  //0+REG_CKG_SR01_MCLK_OFFSET
    auto-enable = <0>;
};

CLK_sr02_mclk: CLK_sr02_mclk {
    #clock-cells = <0>;
    compatible = "sstar,composite-clock";
    clocks = <&CLK_mpll_432m_div16>,<&CLK_mpll_288m_div4>,<&CLK_mpll_246m_div4>,<&CLK_mpll_432m_div8>,<&CLK_upll_384m_div8>,<&CLK_mpll_86m_div2>,<&CLK_mpll_288m_div8>,<&CLK_xtali_24m>,<&CLK_mpll_86m_div4>,<&CLK_xtali_12m>,<&CLK_mpll_86m_div16>,<&CLK_isppll_clk_div2>,<&CLK_isppll_clk_div4>,<&CLK_isppll_clk_div8>,<&CLK_isppll_clk_div16>,<&CLK_VOID>;
    reg = <REG_CKG_SR02_MCLK_BASE 0x4>;
    mux-shift = <10>;  //2+REG_CKG_SR02_MCLK_OFFSET
    mux-width = <4>;
    gate-shift = <8>;  //0+REG_CKG_SR02_MCLK_OFFSET
    auto-enable = <0>;
};

CLK_sr03_mclk: CLK_sr03_mclk {
    #clock-cells = <0>;
    compatible = "sstar,composite-clock";
    clocks = <&CLK_mpll_432m_div16>,<&CLK_mpll_288m_div4>,<&CLK_mpll_246m_div4>,<&CLK_mpll_432m_div8>,<&CLK_upll_384m_div8>,<&CLK_mpll_86m_div2>,<&CLK_mpll_288m_div8>,<&CLK_xtali_24m>,<&CLK_mpll_86m_div4>,<&CLK_xtali_12m>,<&CLK_mpll_86m_div16>,<&CLK_isppll_clk_div2>,<&CLK_isppll_clk_div4>,<&CLK_isppll_clk_div8>,<&CLK_isppll_clk_div16>,<&CLK_VOID>;
    reg = <REG_CKG_SR03_MCLK_BASE 0x4>;
    mux-shift = <10>;  //2+REG_CKG_SR03_MCLK_OFFSET
    mux-width = <4>;
    gate-shift = <8>;  //0+REG_CKG_SR03_MCLK_OFFSET
    auto-enable = <0>;
};

CLK_sr10_mclk: CLK_sr10_mclk {
    #clock-cells = <0>;
    compatible = "sstar,composite-clock";
    clocks = <&CLK_mpll_432m_div16>,<&CLK_mpll_288m_div4>,<&CLK_mpll_246m_div4>,<&CLK_mpll_432m_div8>,<&CLK_upll_384m_div8>,<&CLK_mpll_86m_div2>,<&CLK_mpll_288m_div8>,<&CLK_xtali_24m>,<&CLK_mpll_86m_div4>,<&CLK_xtali_12m>,<&CLK_mpll_86m_div16>,<&CLK_isppll_clk_div2>,<&CLK_isppll_clk_div4>,<&CLK_isppll_clk_div8>,<&CLK_isppll_clk_div16>,<&CLK_VOID>;
    reg = <REG_CKG_SR10_MCLK_BASE 0x4>;
    mux-shift = <2>;  //2+REG_CKG_SR10_MCLK_OFFSET
    mux-width = <4>;
    gate-shift = <0>;  //0+REG_CKG_SR10_MCLK_OFFSET
    auto-enable = <0>;
};

CLK_sr11_mclk: CLK_sr11_mclk {
    #clock-cells = <0>;
    compatible = "sstar,composite-clock";
    clocks = <&CLK_mpll_432m_div16>,<&CLK_mpll_288m_div4>,<&CLK_mpll_246m_div4>,<&CLK_mpll_432m_div8>,<&CLK_upll_384m_div8>,<&CLK_mpll_86m_div2>,<&CLK_mpll_288m_div8>,<&CLK_xtali_24m>,<&CLK_mpll_86m_div4>,<&CLK_xtali_12m>,<&CLK_mpll_86m_div16>,<&CLK_isppll_clk_div2>,<&CLK_isppll_clk_div4>,<&CLK_isppll_clk_div8>,<&CLK_isppll_clk_div16>,<&CLK_VOID>;
    reg = <REG_CKG_SR11_MCLK_BASE 0x4>;
    mux-shift = <10>;  //2+REG_CKG_SR11_MCLK_OFFSET
    mux-width = <4>;
    gate-shift = <8>;  //0+REG_CKG_SR11_MCLK_OFFSET
    auto-enable = <0>;
};

CLK_sr12_mclk: CLK_sr12_mclk {
    #clock-cells = <0>;
    compatible = "sstar,composite-clock";
    clocks = <&CLK_mpll_432m_div16>,<&CLK_mpll_288m_div4>,<&CLK_mpll_246m_div4>,<&CLK_mpll_432m_div8>,<&CLK_upll_384m_div8>,<&CLK_mpll_86m_div2>,<&CLK_mpll_288m_div8>,<&CLK_xtali_24m>,<&CLK_mpll_86m_div4>,<&CLK_xtali_12m>,<&CLK_mpll_86m_div16>,<&CLK_isppll_clk_div2>,<&CLK_isppll_clk_div4>,<&CLK_isppll_clk_div8>,<&CLK_isppll_clk_div16>,<&CLK_VOID>;
    reg = <REG_CKG_SR12_MCLK_BASE 0x4>;
    mux-shift = <2>;  //2+REG_CKG_SR12_MCLK_OFFSET
    mux-width = <4>;
    gate-shift = <0>;  //0+REG_CKG_SR12_MCLK_OFFSET
    auto-enable = <0>;
};

CLK_sr13_mclk: CLK_sr13_mclk {
    #clock-cells = <0>;
    compatible = "sstar,composite-clock";
    clocks = <&CLK_mpll_432m_div16>,<&CLK_mpll_288m_div4>,<&CLK_mpll_246m_div4>,<&CLK_mpll_432m_div8>,<&CLK_upll_384m_div8>,<&CLK_mpll_86m_div2>,<&CLK_mpll_288m_div8>,<&CLK_xtali_24m>,<&CLK_mpll_86m_div4>,<&CLK_xtali_12m>,<&CLK_mpll_86m_div16>,<&CLK_isppll_clk_div2>,<&CLK_isppll_clk_div4>,<&CLK_isppll_clk_div8>,<&CLK_isppll_clk_div16>,<&CLK_VOID>;
    reg = <REG_CKG_SR13_MCLK_BASE 0x4>;
    mux-shift = <10>;  //2+REG_CKG_SR13_MCLK_OFFSET
    mux-width = <4>;
    gate-shift = <8>;  //0+REG_CKG_SR13_MCLK_OFFSET
    auto-enable = <0>;
};

CLK_ssm0: CLK_ssm0 {
    #clock-cells = <0>;
    compatible = "sstar,composite-clock";
    clocks = <&CLK_mpll_432m_div16>,<&CLK_mpll_288m_div4>,<&CLK_mpll_246m_div4>,<&CLK_mpll_432m_div8>,<&CLK_upll_384m_div8>,<&CLK_mpll_86m_div2>,<&CLK_mpll_288m_div8>,<&CLK_xtali_24m>,<&CLK_mpll_86m_div4>,<&CLK_xtali_12m>,<&CLK_mpll_86m_div16>,<&CLK_isppll_clk_div2>,<&CLK_isppll_clk_div4>,<&CLK_isppll_clk_div8>,<&CLK_isppll_clk_div16>,<&CLK_VOID>;
    reg = <REG_CKG_SSM0_BASE 0x4>;
    mux-shift = <2>;  //2+REG_CKG_SSM0_OFFSET
    mux-width = <4>;
    gate-shift = <0>;  //0+REG_CKG_SSM0_OFFSET
    auto-enable = <0>;
};

CLK_ssm1: CLK_ssm1 {
    #clock-cells = <0>;
    compatible = "sstar,composite-clock";
    clocks = <&CLK_mpll_432m_div16>,<&CLK_mpll_288m_div4>,<&CLK_mpll_246m_div4>,<&CLK_mpll_432m_div8>,<&CLK_upll_384m_div8>,<&CLK_mpll_86m_div2>,<&CLK_mpll_288m_div8>,<&CLK_xtali_24m>,<&CLK_mpll_86m_div4>,<&CLK_xtali_12m>,<&CLK_mpll_86m_div16>,<&CLK_isppll_clk_div2>,<&CLK_isppll_clk_div4>,<&CLK_isppll_clk_div8>,<&CLK_isppll_clk_div16>,<&CLK_VOID>;
    reg = <REG_CKG_SSM1_BASE 0x4>;
    mux-shift = <10>;  //2+REG_CKG_SSM1_OFFSET
    mux-width = <4>;
    gate-shift = <8>;  //0+REG_CKG_SSM1_OFFSET
    auto-enable = <0>;
};

CLK_bist_ipu_gp: CLK_bist_ipu_gp {
    #clock-cells = <0>;
    compatible = "sstar,composite-clock";
    clocks = <&CLK_upll_320m>,<&CLK_mpll_288m>,<&CLK_upll_480m_div2>,<&CLK_mpll_432m_div2>,<&CLK_mpll_345m_div2>,<&CLK_mpll_288m_div2>,<&CLK_mpll_432m_div8>,<&CLK_xtali_12m>;
    reg = <REG_CKG_BIST_IPU_GP_BASE 0x4>;
    mux-shift = <2>;  //2+REG_CKG_BIST_IPU_GP_OFFSET
    mux-width = <3>;
    gate-shift = <0>;  //0+REG_CKG_BIST_IPU_GP_OFFSET
    auto-enable = <0>;
};

CLK_ipu: CLK_ipu {
    #clock-cells = <0>;
    compatible = "sstar,composite-clock";
    clocks = <&CLK_xtali_12m>,<&CLK_syspll_600m>,<&CLK_upll_480m>,<&CLK_syspll_400m>,<&CLK_upll_320m>,<&CLK_upll_480m_div2>,<&CLK_mpll_432m_div2>,<&CLK_mpll_691m>;
    reg = <REG_CKG_IPU_BASE 0x4>;
    mux-shift = <2>;  //2+REG_CKG_IPU_OFFSET
    mux-width = <3>;
    gate-shift = <0>;  //0+REG_CKG_IPU_OFFSET
    auto-enable = <0>;
};

CLK_ipuff: CLK_ipuff {
    #clock-cells = <0>;
    compatible = "sstar,composite-clock";
    clocks = <&CLK_mpll_432m>,<&CLK_upll_384m>,<&CLK_upll_320m>,<&CLK_upll_480m_div2>;
    reg = <REG_CKG_IPUFF_BASE 0x4>;
    mux-shift = <10>;  //2+REG_CKG_IPUFF_OFFSET
    mux-width = <2>;
    gate-shift = <8>;  //0+REG_CKG_IPUFF_OFFSET
    auto-enable = <0>;
};

CLK_bist_usb30_drd_gp: CLK_bist_usb30_drd_gp {
    #clock-cells = <0>;
    compatible = "sstar,composite-clock";
    clocks = <&CLK_upll_320m>,<&CLK_mpll_288m>,<&CLK_upll_480m_div2>,<&CLK_mpll_432m_div2>,<&CLK_mpll_345m_div2>,<&CLK_mpll_288m_div2>,<&CLK_mpll_432m_div8>,<&CLK_xtali_12m>;
    reg = <REG_CKG_BIST_USB30_DRD_GP_BASE 0x4>;
    mux-shift = <10>;  //2+REG_CKG_BIST_USB30_DRD_GP_OFFSET
    mux-width = <3>;
    gate-shift = <8>;  //0+REG_CKG_BIST_USB30_DRD_GP_OFFSET
    auto-enable = <0>;
};

CLK_sof_usb30_drd: CLK_sof_usb30_drd {
    #clock-cells = <0>;
    compatible = "sstar,composite-clock";
    clocks = <&CLK_xtali_24m>,<&CLK_upll_384m_div8>,<&CLK_mpll_432m_div8>,<&CLK_mpll_432m_div4>;
    reg = <REG_CKG_SOF_USB30_DRD_BASE 0x4>;
    mux-shift = <2>;  //2+REG_CKG_SOF_USB30_DRD_OFFSET
    mux-width = <2>;
    gate-shift = <0>;  //0+REG_CKG_SOF_USB30_DRD_OFFSET
    auto-enable = <0>;
};

CLK_ssusb_phy_108: CLK_ssusb_phy_108 {
    #clock-cells = <0>;
    compatible = "sstar,composite-clock";
    clocks = <&CLK_mpll_432m_div4>,<&CLK_VOID>,<&CLK_VOID>,<&CLK_VOID>;
    reg = <REG_CKG_SSUSB_PHY_108_BASE 0x4>;
    mux-shift = <2>;  //2+REG_CKG_SSUSB_PHY_108_OFFSET
    mux-width = <2>;
    gate-shift = <0>;  //0+REG_CKG_SSUSB_PHY_108_OFFSET
    auto-enable = <0>;
};

CLK_ssusb_phy_432: CLK_ssusb_phy_432 {
    #clock-cells = <0>;
    compatible = "sstar,composite-clock";
    clocks = <&CLK_mpll_432m>,<&CLK_VOID>,<&CLK_VOID>,<&CLK_VOID>;
    reg = <REG_CKG_SSUSB_PHY_432_BASE 0x4>;
    mux-shift = <6>;  //2+REG_CKG_SSUSB_PHY_432_OFFSET
    mux-width = <2>;
    gate-shift = <4>;  //0+REG_CKG_SSUSB_PHY_432_OFFSET
    auto-enable = <0>;
};

CLK_bist_sata_gp: CLK_bist_sata_gp {
    #clock-cells = <0>;
    compatible = "sstar,composite-clock";
    clocks = <&CLK_upll_320m>,<&CLK_mpll_288m>,<&CLK_upll_480m_div2>,<&CLK_mpll_432m_div2>,<&CLK_mpll_345m_div2>,<&CLK_mpll_288m_div2>,<&CLK_mpll_432m_div8>,<&CLK_xtali_12m>;
    reg = <REG_CKG_BIST_SATA_GP_BASE 0x4>;
    mux-shift = <2>;  //2+REG_CKG_BIST_SATA_GP_OFFSET
    mux-width = <3>;
    gate-shift = <0>;  //0+REG_CKG_BIST_SATA_GP_OFFSET
    auto-enable = <0>;
};

CLK_sata_pm: CLK_sata_pm {
    #clock-cells = <0>;
    compatible = "sstar,composite-clock";
    clocks = <&CLK_mpll_432m_div4>,<&CLK_xtali_24m>,<&CLK_VOID>,<&CLK_VOID>;
    reg = <REG_CKG_SATA_PM_BASE 0x4>;
    mux-shift = <10>;  //2+REG_CKG_SATA_PM_OFFSET
    mux-width = <2>;
    gate-shift = <8>;  //0+REG_CKG_SATA_PM_OFFSET
    auto-enable = <0>;
};

CLK_sata_phy_108: CLK_sata_phy_108 {
    #clock-cells = <0>;
    compatible = "sstar,composite-clock";
    clocks = <&CLK_mpll_432m_div4>,<&CLK_VOID>,<&CLK_VOID>,<&CLK_VOID>;
    reg = <REG_CKG_SATA_PHY_108_BASE 0x4>;
    mux-shift = <2>;  //2+REG_CKG_SATA_PHY_108_OFFSET
    mux-width = <2>;
    gate-shift = <0>;  //0+REG_CKG_SATA_PHY_108_OFFSET
    auto-enable = <0>;
};

CLK_sata_phy_432: CLK_sata_phy_432 {
    #clock-cells = <0>;
    compatible = "sstar,composite-clock";
    clocks = <&CLK_mpll_432m>,<&CLK_VOID>,<&CLK_VOID>,<&CLK_VOID>;
    reg = <REG_CKG_SATA_PHY_432_BASE 0x4>;
    mux-shift = <6>;  //2+REG_CKG_SATA_PHY_432_OFFSET
    mux-width = <2>;
    gate-shift = <4>;  //0+REG_CKG_SATA_PHY_432_OFFSET
    auto-enable = <0>;
};

CLK_bist_sata2_gp: CLK_bist_sata2_gp {
    #clock-cells = <0>;
    compatible = "sstar,composite-clock";
    clocks = <&CLK_upll_320m>,<&CLK_mpll_288m>,<&CLK_upll_480m_div2>,<&CLK_mpll_432m_div2>,<&CLK_mpll_345m_div2>,<&CLK_mpll_288m_div2>,<&CLK_mpll_432m_div8>,<&CLK_xtali_12m>;
    reg = <REG_CKG_BIST_SATA2_GP_BASE 0x4>;
    mux-shift = <2>;  //2+REG_CKG_BIST_SATA2_GP_OFFSET
    mux-width = <3>;
    gate-shift = <0>;  //0+REG_CKG_BIST_SATA2_GP_OFFSET
    auto-enable = <0>;
};

CLK_sata2_pm: CLK_sata2_pm {
    #clock-cells = <0>;
    compatible = "sstar,composite-clock";
    clocks = <&CLK_mpll_432m_div4>,<&CLK_xtali_24m>,<&CLK_VOID>,<&CLK_VOID>;
    reg = <REG_CKG_SATA2_PM_BASE 0x4>;
    mux-shift = <2>;  //2+REG_CKG_SATA2_PM_OFFSET
    mux-width = <2>;
    gate-shift = <0>;  //0+REG_CKG_SATA2_PM_OFFSET
    auto-enable = <0>;
};

CLK_sata2_phy_108: CLK_sata2_phy_108 {
    #clock-cells = <0>;
    compatible = "sstar,composite-clock";
    clocks = <&CLK_mpll_432m_div4>,<&CLK_VOID>,<&CLK_VOID>,<&CLK_VOID>;
    reg = <REG_CKG_SATA2_PHY_108_BASE 0x4>;
    mux-shift = <2>;  //2+REG_CKG_SATA2_PHY_108_OFFSET
    mux-width = <2>;
    gate-shift = <0>;  //0+REG_CKG_SATA2_PHY_108_OFFSET
    auto-enable = <0>;
};

CLK_sata2_phy_432: CLK_sata2_phy_432 {
    #clock-cells = <0>;
    compatible = "sstar,composite-clock";
    clocks = <&CLK_mpll_432m>,<&CLK_VOID>,<&CLK_VOID>,<&CLK_VOID>;
    reg = <REG_CKG_SATA2_PHY_432_BASE 0x4>;
    mux-shift = <2>;  //2+REG_CKG_SATA2_PHY_432_OFFSET
    mux-width = <2>;
    gate-shift = <0>;  //0+REG_CKG_SATA2_PHY_432_OFFSET
    auto-enable = <0>;
};

CLK_csi_mac_lptx_top_i_a0: CLK_csi_mac_lptx_top_i_a0 {
    #clock-cells = <0>;
    compatible = "sstar,composite-clock";
    clocks = <&CLK_mpll_432m>,<&CLK_upll_384m>,<&CLK_upll_320m>,<&CLK_mpll_288m>,<&CLK_upll_480m_div2>,<&CLK_mpll_432m_div2>,<&CLK_mpll_345m_div2>,<&CLK_mpll_288m_div2>;
    reg = <REG_CKG_CSI_MAC_LPTX_TOP_I_A0_BASE 0x4>;
    mux-shift = <2>;  //2+REG_CKG_CSI_MAC_LPTX_TOP_I_A0_OFFSET
    mux-width = <3>;
    gate-shift = <0>;  //0+REG_CKG_CSI_MAC_LPTX_TOP_I_A0_OFFSET
    auto-enable = <0>;
};

CLK_csi_mac_top_i_a0: CLK_csi_mac_top_i_a0 {
    #clock-cells = <0>;
    compatible = "sstar,composite-clock";
    clocks = <&CLK_mpll_432m>,<&CLK_upll_384m>,<&CLK_upll_320m>,<&CLK_mpll_288m>,<&CLK_upll_480m_div2>,<&CLK_mpll_432m_div2>,<&CLK_mpll_345m_div2>,<&CLK_mpll_288m_div2>;
    reg = <REG_CKG_CSI_MAC_TOP_I_A0_BASE 0x4>;
    mux-shift = <10>;  //2+REG_CKG_CSI_MAC_TOP_I_A0_OFFSET
    mux-width = <3>;
    gate-shift = <8>;  //0+REG_CKG_CSI_MAC_TOP_I_A0_OFFSET
    auto-enable = <0>;
};

CLK_ns_top_i_a0: CLK_ns_top_i_a0 {
    #clock-cells = <0>;
    compatible = "sstar,composite-clock";
    clocks = <&CLK_mpll_432m>,<&CLK_upll_384m>,<&CLK_upll_320m>,<&CLK_mpll_288m>,<&CLK_upll_480m_div2>,<&CLK_mpll_432m_div2>,<&CLK_mpll_345m_div2>,<&CLK_mpll_288m_div2>;
    reg = <REG_CKG_NS_TOP_I_A0_BASE 0x4>;
    mux-shift = <2>;  //2+REG_CKG_NS_TOP_I_A0_OFFSET
    mux-width = <3>;
    gate-shift = <0>;  //0+REG_CKG_NS_TOP_I_A0_OFFSET
    auto-enable = <0>;
};

CLK_csi_mac_lptx_top_i_a1: CLK_csi_mac_lptx_top_i_a1 {
    #clock-cells = <0>;
    compatible = "sstar,composite-clock";
    clocks = <&CLK_mpll_432m>,<&CLK_upll_384m>,<&CLK_upll_320m>,<&CLK_mpll_288m>,<&CLK_upll_480m_div2>,<&CLK_mpll_432m_div2>,<&CLK_mpll_345m_div2>,<&CLK_mpll_288m_div2>;
    reg = <REG_CKG_CSI_MAC_LPTX_TOP_I_A1_BASE 0x4>;
    mux-shift = <10>;  //2+REG_CKG_CSI_MAC_LPTX_TOP_I_A1_OFFSET
    mux-width = <3>;
    gate-shift = <8>;  //0+REG_CKG_CSI_MAC_LPTX_TOP_I_A1_OFFSET
    auto-enable = <0>;
};

CLK_csi_mac_top_i_a1: CLK_csi_mac_top_i_a1 {
    #clock-cells = <0>;
    compatible = "sstar,composite-clock";
    clocks = <&CLK_mpll_432m>,<&CLK_upll_384m>,<&CLK_upll_320m>,<&CLK_mpll_288m>,<&CLK_upll_480m_div2>,<&CLK_mpll_432m_div2>,<&CLK_mpll_345m_div2>,<&CLK_mpll_288m_div2>;
    reg = <REG_CKG_CSI_MAC_TOP_I_A1_BASE 0x4>;
    mux-shift = <2>;  //2+REG_CKG_CSI_MAC_TOP_I_A1_OFFSET
    mux-width = <3>;
    gate-shift = <0>;  //0+REG_CKG_CSI_MAC_TOP_I_A1_OFFSET
    auto-enable = <0>;
};

CLK_ns_top_i_a1: CLK_ns_top_i_a1 {
    #clock-cells = <0>;
    compatible = "sstar,composite-clock";
    clocks = <&CLK_mpll_432m>,<&CLK_upll_384m>,<&CLK_upll_320m>,<&CLK_mpll_288m>,<&CLK_upll_480m_div2>,<&CLK_mpll_432m_div2>,<&CLK_mpll_345m_div2>,<&CLK_mpll_288m_div2>;
    reg = <REG_CKG_NS_TOP_I_A1_BASE 0x4>;
    mux-shift = <10>;  //2+REG_CKG_NS_TOP_I_A1_OFFSET
    mux-width = <3>;
    gate-shift = <8>;  //0+REG_CKG_NS_TOP_I_A1_OFFSET
    auto-enable = <0>;
};

CLK_csi_mac_lptx_top_i_a2: CLK_csi_mac_lptx_top_i_a2 {
    #clock-cells = <0>;
    compatible = "sstar,composite-clock";
    clocks = <&CLK_mpll_432m>,<&CLK_upll_384m>,<&CLK_upll_320m>,<&CLK_mpll_288m>,<&CLK_upll_480m_div2>,<&CLK_mpll_432m_div2>,<&CLK_mpll_345m_div2>,<&CLK_mpll_288m_div2>;
    reg = <REG_CKG_CSI_MAC_LPTX_TOP_I_A2_BASE 0x4>;
    mux-shift = <2>;  //2+REG_CKG_CSI_MAC_LPTX_TOP_I_A2_OFFSET
    mux-width = <3>;
    gate-shift = <0>;  //0+REG_CKG_CSI_MAC_LPTX_TOP_I_A2_OFFSET
    auto-enable = <0>;
};

CLK_csi_mac_top_i_a2: CLK_csi_mac_top_i_a2 {
    #clock-cells = <0>;
    compatible = "sstar,composite-clock";
    clocks = <&CLK_mpll_432m>,<&CLK_upll_384m>,<&CLK_upll_320m>,<&CLK_mpll_288m>,<&CLK_upll_480m_div2>,<&CLK_mpll_432m_div2>,<&CLK_mpll_345m_div2>,<&CLK_mpll_288m_div2>;
    reg = <REG_CKG_CSI_MAC_TOP_I_A2_BASE 0x4>;
    mux-shift = <10>;  //2+REG_CKG_CSI_MAC_TOP_I_A2_OFFSET
    mux-width = <3>;
    gate-shift = <8>;  //0+REG_CKG_CSI_MAC_TOP_I_A2_OFFSET
    auto-enable = <0>;
};

CLK_ns_top_i_a2: CLK_ns_top_i_a2 {
    #clock-cells = <0>;
    compatible = "sstar,composite-clock";
    clocks = <&CLK_mpll_432m>,<&CLK_upll_384m>,<&CLK_upll_320m>,<&CLK_mpll_288m>,<&CLK_upll_480m_div2>,<&CLK_mpll_432m_div2>,<&CLK_mpll_345m_div2>,<&CLK_mpll_288m_div2>;
    reg = <REG_CKG_NS_TOP_I_A2_BASE 0x4>;
    mux-shift = <2>;  //2+REG_CKG_NS_TOP_I_A2_OFFSET
    mux-width = <3>;
    gate-shift = <0>;  //0+REG_CKG_NS_TOP_I_A2_OFFSET
    auto-enable = <0>;
};

CLK_csi_mac_lptx_top_i_a3: CLK_csi_mac_lptx_top_i_a3 {
    #clock-cells = <0>;
    compatible = "sstar,composite-clock";
    clocks = <&CLK_mpll_432m>,<&CLK_upll_384m>,<&CLK_upll_320m>,<&CLK_mpll_288m>,<&CLK_upll_480m_div2>,<&CLK_mpll_432m_div2>,<&CLK_mpll_345m_div2>,<&CLK_mpll_288m_div2>;
    reg = <REG_CKG_CSI_MAC_LPTX_TOP_I_A3_BASE 0x4>;
    mux-shift = <2>;  //2+REG_CKG_CSI_MAC_LPTX_TOP_I_A3_OFFSET
    mux-width = <3>;
    gate-shift = <0>;  //0+REG_CKG_CSI_MAC_LPTX_TOP_I_A3_OFFSET
    auto-enable = <0>;
};

CLK_csi_mac_top_i_a3: CLK_csi_mac_top_i_a3 {
    #clock-cells = <0>;
    compatible = "sstar,composite-clock";
    clocks = <&CLK_mpll_432m>,<&CLK_upll_384m>,<&CLK_upll_320m>,<&CLK_mpll_288m>,<&CLK_upll_480m_div2>,<&CLK_mpll_432m_div2>,<&CLK_mpll_345m_div2>,<&CLK_mpll_288m_div2>;
    reg = <REG_CKG_CSI_MAC_TOP_I_A3_BASE 0x4>;
    mux-shift = <10>;  //2+REG_CKG_CSI_MAC_TOP_I_A3_OFFSET
    mux-width = <3>;
    gate-shift = <8>;  //0+REG_CKG_CSI_MAC_TOP_I_A3_OFFSET
    auto-enable = <0>;
};

CLK_ns_top_i_a3: CLK_ns_top_i_a3 {
    #clock-cells = <0>;
    compatible = "sstar,composite-clock";
    clocks = <&CLK_mpll_432m>,<&CLK_upll_384m>,<&CLK_upll_320m>,<&CLK_mpll_288m>,<&CLK_upll_480m_div2>,<&CLK_mpll_432m_div2>,<&CLK_mpll_345m_div2>,<&CLK_mpll_288m_div2>;
    reg = <REG_CKG_NS_TOP_I_A3_BASE 0x4>;
    mux-shift = <2>;  //2+REG_CKG_NS_TOP_I_A3_OFFSET
    mux-width = <3>;
    gate-shift = <0>;  //0+REG_CKG_NS_TOP_I_A3_OFFSET
    auto-enable = <0>;
};

CLK_csi_mac_lptx_top_i_b0: CLK_csi_mac_lptx_top_i_b0 {
    #clock-cells = <0>;
    compatible = "sstar,composite-clock";
    clocks = <&CLK_mpll_432m>,<&CLK_upll_384m>,<&CLK_upll_320m>,<&CLK_mpll_288m>,<&CLK_upll_480m_div2>,<&CLK_mpll_432m_div2>,<&CLK_mpll_345m_div2>,<&CLK_mpll_288m_div2>;
    reg = <REG_CKG_CSI_MAC_LPTX_TOP_I_B0_BASE 0x4>;
    mux-shift = <2>;  //2+REG_CKG_CSI_MAC_LPTX_TOP_I_B0_OFFSET
    mux-width = <3>;
    gate-shift = <0>;  //0+REG_CKG_CSI_MAC_LPTX_TOP_I_B0_OFFSET
    auto-enable = <0>;
};

CLK_csi_mac_top_i_b0: CLK_csi_mac_top_i_b0 {
    #clock-cells = <0>;
    compatible = "sstar,composite-clock";
    clocks = <&CLK_mpll_432m>,<&CLK_upll_384m>,<&CLK_upll_320m>,<&CLK_mpll_288m>,<&CLK_upll_480m_div2>,<&CLK_mpll_432m_div2>,<&CLK_mpll_345m_div2>,<&CLK_mpll_288m_div2>;
    reg = <REG_CKG_CSI_MAC_TOP_I_B0_BASE 0x4>;
    mux-shift = <10>;  //2+REG_CKG_CSI_MAC_TOP_I_B0_OFFSET
    mux-width = <3>;
    gate-shift = <8>;  //0+REG_CKG_CSI_MAC_TOP_I_B0_OFFSET
    auto-enable = <0>;
};

CLK_ns_top_i_b0: CLK_ns_top_i_b0 {
    #clock-cells = <0>;
    compatible = "sstar,composite-clock";
    clocks = <&CLK_mpll_432m>,<&CLK_upll_384m>,<&CLK_upll_320m>,<&CLK_mpll_288m>,<&CLK_upll_480m_div2>,<&CLK_mpll_432m_div2>,<&CLK_mpll_345m_div2>,<&CLK_mpll_288m_div2>;
    reg = <REG_CKG_NS_TOP_I_B0_BASE 0x4>;
    mux-shift = <2>;  //2+REG_CKG_NS_TOP_I_B0_OFFSET
    mux-width = <3>;
    gate-shift = <0>;  //0+REG_CKG_NS_TOP_I_B0_OFFSET
    auto-enable = <0>;
};

CLK_csi_mac_lptx_top_i_b1: CLK_csi_mac_lptx_top_i_b1 {
    #clock-cells = <0>;
    compatible = "sstar,composite-clock";
    clocks = <&CLK_mpll_432m>,<&CLK_upll_384m>,<&CLK_upll_320m>,<&CLK_mpll_288m>,<&CLK_upll_480m_div2>,<&CLK_mpll_432m_div2>,<&CLK_mpll_345m_div2>,<&CLK_mpll_288m_div2>;
    reg = <REG_CKG_CSI_MAC_LPTX_TOP_I_B1_BASE 0x4>;
    mux-shift = <10>;  //2+REG_CKG_CSI_MAC_LPTX_TOP_I_B1_OFFSET
    mux-width = <3>;
    gate-shift = <8>;  //0+REG_CKG_CSI_MAC_LPTX_TOP_I_B1_OFFSET
    auto-enable = <0>;
};

CLK_csi_mac_top_i_b1: CLK_csi_mac_top_i_b1 {
    #clock-cells = <0>;
    compatible = "sstar,composite-clock";
    clocks = <&CLK_mpll_432m>,<&CLK_upll_384m>,<&CLK_upll_320m>,<&CLK_mpll_288m>,<&CLK_upll_480m_div2>,<&CLK_mpll_432m_div2>,<&CLK_mpll_345m_div2>,<&CLK_mpll_288m_div2>;
    reg = <REG_CKG_CSI_MAC_TOP_I_B1_BASE 0x4>;
    mux-shift = <2>;  //2+REG_CKG_CSI_MAC_TOP_I_B1_OFFSET
    mux-width = <3>;
    gate-shift = <0>;  //0+REG_CKG_CSI_MAC_TOP_I_B1_OFFSET
    auto-enable = <0>;
};

CLK_ns_top_i_b1: CLK_ns_top_i_b1 {
    #clock-cells = <0>;
    compatible = "sstar,composite-clock";
    clocks = <&CLK_mpll_432m>,<&CLK_upll_384m>,<&CLK_upll_320m>,<&CLK_mpll_288m>,<&CLK_upll_480m_div2>,<&CLK_mpll_432m_div2>,<&CLK_mpll_345m_div2>,<&CLK_mpll_288m_div2>;
    reg = <REG_CKG_NS_TOP_I_B1_BASE 0x4>;
    mux-shift = <10>;  //2+REG_CKG_NS_TOP_I_B1_OFFSET
    mux-width = <3>;
    gate-shift = <8>;  //0+REG_CKG_NS_TOP_I_B1_OFFSET
    auto-enable = <0>;
};

CLK_csi_mac_lptx_top_i_b2: CLK_csi_mac_lptx_top_i_b2 {
    #clock-cells = <0>;
    compatible = "sstar,composite-clock";
    clocks = <&CLK_mpll_432m>,<&CLK_upll_384m>,<&CLK_upll_320m>,<&CLK_mpll_288m>,<&CLK_upll_480m_div2>,<&CLK_mpll_432m_div2>,<&CLK_mpll_345m_div2>,<&CLK_mpll_288m_div2>;
    reg = <REG_CKG_CSI_MAC_LPTX_TOP_I_B2_BASE 0x4>;
    mux-shift = <2>;  //2+REG_CKG_CSI_MAC_LPTX_TOP_I_B2_OFFSET
    mux-width = <3>;
    gate-shift = <0>;  //0+REG_CKG_CSI_MAC_LPTX_TOP_I_B2_OFFSET
    auto-enable = <0>;
};

CLK_csi_mac_top_i_b2: CLK_csi_mac_top_i_b2 {
    #clock-cells = <0>;
    compatible = "sstar,composite-clock";
    clocks = <&CLK_mpll_432m>,<&CLK_upll_384m>,<&CLK_upll_320m>,<&CLK_mpll_288m>,<&CLK_upll_480m_div2>,<&CLK_mpll_432m_div2>,<&CLK_mpll_345m_div2>,<&CLK_mpll_288m_div2>;
    reg = <REG_CKG_CSI_MAC_TOP_I_B2_BASE 0x4>;
    mux-shift = <10>;  //2+REG_CKG_CSI_MAC_TOP_I_B2_OFFSET
    mux-width = <3>;
    gate-shift = <8>;  //0+REG_CKG_CSI_MAC_TOP_I_B2_OFFSET
    auto-enable = <0>;
};

CLK_ns_top_i_b2: CLK_ns_top_i_b2 {
    #clock-cells = <0>;
    compatible = "sstar,composite-clock";
    clocks = <&CLK_mpll_432m>,<&CLK_upll_384m>,<&CLK_upll_320m>,<&CLK_mpll_288m>,<&CLK_upll_480m_div2>,<&CLK_mpll_432m_div2>,<&CLK_mpll_345m_div2>,<&CLK_mpll_288m_div2>;
    reg = <REG_CKG_NS_TOP_I_B2_BASE 0x4>;
    mux-shift = <2>;  //2+REG_CKG_NS_TOP_I_B2_OFFSET
    mux-width = <3>;
    gate-shift = <0>;  //0+REG_CKG_NS_TOP_I_B2_OFFSET
    auto-enable = <0>;
};

CLK_csi_mac_lptx_top_i_b3: CLK_csi_mac_lptx_top_i_b3 {
    #clock-cells = <0>;
    compatible = "sstar,composite-clock";
    clocks = <&CLK_mpll_432m>,<&CLK_upll_384m>,<&CLK_upll_320m>,<&CLK_mpll_288m>,<&CLK_upll_480m_div2>,<&CLK_mpll_432m_div2>,<&CLK_mpll_345m_div2>,<&CLK_mpll_288m_div2>;
    reg = <REG_CKG_CSI_MAC_LPTX_TOP_I_B3_BASE 0x4>;
    mux-shift = <2>;  //2+REG_CKG_CSI_MAC_LPTX_TOP_I_B3_OFFSET
    mux-width = <3>;
    gate-shift = <0>;  //0+REG_CKG_CSI_MAC_LPTX_TOP_I_B3_OFFSET
    auto-enable = <0>;
};

CLK_csi_mac_top_i_b3: CLK_csi_mac_top_i_b3 {
    #clock-cells = <0>;
    compatible = "sstar,composite-clock";
    clocks = <&CLK_mpll_432m>,<&CLK_upll_384m>,<&CLK_upll_320m>,<&CLK_mpll_288m>,<&CLK_upll_480m_div2>,<&CLK_mpll_432m_div2>,<&CLK_mpll_345m_div2>,<&CLK_mpll_288m_div2>;
    reg = <REG_CKG_CSI_MAC_TOP_I_B3_BASE 0x4>;
    mux-shift = <10>;  //2+REG_CKG_CSI_MAC_TOP_I_B3_OFFSET
    mux-width = <3>;
    gate-shift = <8>;  //0+REG_CKG_CSI_MAC_TOP_I_B3_OFFSET
    auto-enable = <0>;
};

CLK_ns_top_i_b3: CLK_ns_top_i_b3 {
    #clock-cells = <0>;
    compatible = "sstar,composite-clock";
    clocks = <&CLK_mpll_432m>,<&CLK_upll_384m>,<&CLK_upll_320m>,<&CLK_mpll_288m>,<&CLK_upll_480m_div2>,<&CLK_mpll_432m_div2>,<&CLK_mpll_345m_div2>,<&CLK_mpll_288m_div2>;
    reg = <REG_CKG_NS_TOP_I_B3_BASE 0x4>;
    mux-shift = <2>;  //2+REG_CKG_NS_TOP_I_B3_OFFSET
    mux-width = <3>;
    gate-shift = <0>;  //0+REG_CKG_NS_TOP_I_B3_OFFSET
    auto-enable = <0>;
};

CLK_mipi_tx_csi: CLK_mipi_tx_csi {
    #clock-cells = <0>;
    compatible = "sstar,composite-clock";
    clocks = <&CLK_lpll_clk>,<&CLK_upll_320m_div2>,<&CLK_mpll_288m_div2>,<&CLK_mpll_432m_div4>,<&CLK_mpll_432m_div2>,<&CLK_upll_480m_div2>,<&CLK_mpll_288m>,<&CLK_upll_320m>;
    reg = <REG_CKG_MIPI_TX_CSI_BASE 0x4>;
    mux-shift = <10>;  //2+REG_CKG_MIPI_TX_CSI_OFFSET
    mux-width = <3>;
    gate-shift = <8>;  //0+REG_CKG_MIPI_TX_CSI_OFFSET
    auto-enable = <0>;
};

CLK_mipi_tx_dsi: CLK_mipi_tx_dsi {
    #clock-cells = <0>;
    compatible = "sstar,composite-clock";
    clocks = <&CLK_lpll_clk>,<&CLK_upll_320m_div2>,<&CLK_mpll_288m_div2>,<&CLK_mpll_432m_div4>,<&CLK_mpll_432m_div2>,<&CLK_upll_480m_div2>,<&CLK_VOID>,<&CLK_VOID>;
    reg = <REG_CKG_MIPI_TX_DSI_BASE 0x4>;
    mux-shift = <10>;  //2+REG_CKG_MIPI_TX_DSI_OFFSET
    mux-width = <3>;
    gate-shift = <8>;  //0+REG_CKG_MIPI_TX_DSI_OFFSET
    auto-enable = <0>;
};

CLK_bist_vhe_gp: CLK_bist_vhe_gp {
    #clock-cells = <0>;
    compatible = "sstar,composite-clock";
    clocks = <&CLK_upll_320m>,<&CLK_mpll_288m>,<&CLK_upll_480m_div2>,<&CLK_mpll_432m_div2>,<&CLK_mpll_345m_div2>,<&CLK_mpll_288m_div2>,<&CLK_mpll_432m_div8>,<&CLK_xtali_12m>;
    reg = <REG_CKG_BIST_VHE_GP_BASE 0x4>;
    mux-shift = <10>;  //2+REG_CKG_BIST_VHE_GP_OFFSET
    mux-width = <3>;
    gate-shift = <8>;  //0+REG_CKG_BIST_VHE_GP_OFFSET
    auto-enable = <0>;
};

CLK_vhe: CLK_vhe {
    #clock-cells = <0>;
    compatible = "sstar,composite-clock";
    clocks = <&CLK_ven_pll>,<&CLK_syspll_600m>,<&CLK_miupll_clk>,<&CLK_upll_480m>,<&CLK_mpll_432m>,<&CLK_upll_384m>,<&CLK_upll_320m>,<&CLK_mpll_288m>;
    reg = <REG_CKG_VHE_BASE 0x4>;
    mux-shift = <2>;  //2+REG_CKG_VHE_OFFSET
    mux-width = <3>;
    gate-shift = <7>;  //0+REG_CKG_VHE_OFFSET
    auto-enable = <0>;
};

CLK_mfe: CLK_mfe {
    #clock-cells = <0>;
    compatible = "sstar,composite-clock";
    clocks = <&CLK_ven_pll>,<&CLK_syspll_600m>,<&CLK_miupll_clk>,<&CLK_upll_480m>,<&CLK_mpll_432m>,<&CLK_upll_384m>,<&CLK_upll_320m>,<&CLK_mpll_288m>;
    reg = <REG_CKG_MFE_BASE 0x4>;
    mux-shift = <2>;  //2+REG_CKG_MFE_OFFSET
    mux-width = <3>;
    gate-shift = <0>;  //0+REG_CKG_MFE_OFFSET
    auto-enable = <0>;
};

CLK_ven_axi: CLK_ven_axi {
    #clock-cells = <0>;
    compatible = "sstar,composite-clock";
    clocks = <&CLK_ven_pll>,<&CLK_syspll_600m>,<&CLK_miupll_clk>,<&CLK_upll_480m>,<&CLK_mpll_432m>,<&CLK_upll_384m>,<&CLK_upll_320m>,<&CLK_mpll_288m>;
    reg = <REG_CKG_VEN_AXI_BASE 0x4>;
    mux-shift = <10>;  //2+REG_CKG_VEN_AXI_OFFSET
    mux-width = <3>;
    gate-shift = <8>;  //0+REG_CKG_VEN_AXI_OFFSET
    auto-enable = <0>;
};

CLK_bist_vhe1_gp: CLK_bist_vhe1_gp {
    #clock-cells = <0>;
    compatible = "sstar,composite-clock";
    clocks = <&CLK_upll_320m>,<&CLK_mpll_288m>,<&CLK_upll_480m_div2>,<&CLK_mpll_432m_div2>,<&CLK_mpll_345m_div2>,<&CLK_mpll_288m_div2>,<&CLK_mpll_432m_div8>,<&CLK_xtali_12m>;
    reg = <REG_CKG_BIST_VHE1_GP_BASE 0x4>;
    mux-shift = <2>;  //2+REG_CKG_BIST_VHE1_GP_OFFSET
    mux-width = <3>;
    gate-shift = <0>;  //0+REG_CKG_BIST_VHE1_GP_OFFSET
    auto-enable = <0>;
};

CLK_vhe1: CLK_vhe1 {
    #clock-cells = <0>;
    compatible = "sstar,composite-clock";
    clocks = <&CLK_ven_pll>,<&CLK_syspll_600m>,<&CLK_miupll_clk>,<&CLK_upll_480m>,<&CLK_mpll_432m>,<&CLK_upll_384m>,<&CLK_upll_320m>,<&CLK_mpll_288m>;
    reg = <REG_CKG_VHE1_BASE 0x4>;
    mux-shift = <2>;  //2+REG_CKG_VHE1_OFFSET
    mux-width = <3>;
    gate-shift = <0>;  //0+REG_CKG_VHE1_OFFSET
    auto-enable = <0>;
};

CLK_mfe1: CLK_mfe1 {
    #clock-cells = <0>;
    compatible = "sstar,composite-clock";
    clocks = <&CLK_ven_pll>,<&CLK_syspll_600m>,<&CLK_miupll_clk>,<&CLK_upll_480m>,<&CLK_mpll_432m>,<&CLK_upll_384m>,<&CLK_upll_320m>,<&CLK_mpll_288m>;
    reg = <REG_CKG_MFE1_BASE 0x4>;
    mux-shift = <2>;  //2+REG_CKG_MFE1_OFFSET
    mux-width = <3>;
    gate-shift = <0>;  //0+REG_CKG_MFE1_OFFSET
    auto-enable = <0>;
};

CLK_ven1_axi: CLK_ven1_axi {
    #clock-cells = <0>;
    compatible = "sstar,composite-clock";
    clocks = <&CLK_ven_pll>,<&CLK_syspll_600m>,<&CLK_miupll_clk>,<&CLK_upll_480m>,<&CLK_mpll_432m>,<&CLK_upll_384m>,<&CLK_upll_320m>,<&CLK_mpll_288m>;
    reg = <REG_CKG_VEN1_AXI_BASE 0x4>;
    mux-shift = <2>;  //2+REG_CKG_VEN1_AXI_OFFSET
    mux-width = <3>;
    gate-shift = <0>;  //0+REG_CKG_VEN1_AXI_OFFSET
    auto-enable = <0>;
};

CLK_bist_vhe2_gp: CLK_bist_vhe2_gp {
    #clock-cells = <0>;
    compatible = "sstar,composite-clock";
    clocks = <&CLK_upll_320m>,<&CLK_mpll_288m>,<&CLK_upll_480m_div2>,<&CLK_mpll_432m_div2>,<&CLK_mpll_345m_div2>,<&CLK_mpll_288m_div2>,<&CLK_mpll_432m_div8>,<&CLK_xtali_12m>;
    reg = <REG_CKG_BIST_VHE2_GP_BASE 0x4>;
    mux-shift = <2>;  //2+REG_CKG_BIST_VHE2_GP_OFFSET
    mux-width = <3>;
    gate-shift = <0>;  //0+REG_CKG_BIST_VHE2_GP_OFFSET
    auto-enable = <0>;
};

CLK_vhe2: CLK_vhe2 {
    #clock-cells = <0>;
    compatible = "sstar,composite-clock";
    clocks = <&CLK_ven_pll>,<&CLK_syspll_600m>,<&CLK_miupll_clk>,<&CLK_upll_480m>,<&CLK_mpll_432m>,<&CLK_upll_384m>,<&CLK_upll_320m>,<&CLK_mpll_288m>;
    reg = <REG_CKG_VHE2_BASE 0x4>;
    mux-shift = <2>;  //2+REG_CKG_VHE2_OFFSET
    mux-width = <3>;
    gate-shift = <0>;  //0+REG_CKG_VHE2_OFFSET
    auto-enable = <0>;
};

CLK_mfe2: CLK_mfe2 {
    #clock-cells = <0>;
    compatible = "sstar,composite-clock";
    clocks = <&CLK_ven_pll>,<&CLK_syspll_600m>,<&CLK_miupll_clk>,<&CLK_upll_480m>,<&CLK_mpll_432m>,<&CLK_upll_384m>,<&CLK_upll_320m>,<&CLK_mpll_288m>;
    reg = <REG_CKG_MFE2_BASE 0x4>;
    mux-shift = <2>;  //2+REG_CKG_MFE2_OFFSET
    mux-width = <3>;
    gate-shift = <0>;  //0+REG_CKG_MFE2_OFFSET
    auto-enable = <0>;
};

CLK_ven2_axi: CLK_ven2_axi {
    #clock-cells = <0>;
    compatible = "sstar,composite-clock";
    clocks = <&CLK_ven_pll>,<&CLK_syspll_600m>,<&CLK_miupll_clk>,<&CLK_upll_480m>,<&CLK_mpll_432m>,<&CLK_upll_384m>,<&CLK_upll_320m>,<&CLK_mpll_288m>;
    reg = <REG_CKG_VEN2_AXI_BASE 0x4>;
    mux-shift = <2>;  //2+REG_CKG_VEN2_AXI_OFFSET
    mux-width = <3>;
    gate-shift = <0>;  //0+REG_CKG_VEN2_AXI_OFFSET
    auto-enable = <0>;
};

CLK_bist_vhe3_gp: CLK_bist_vhe3_gp {
    #clock-cells = <0>;
    compatible = "sstar,composite-clock";
    clocks = <&CLK_upll_320m>,<&CLK_mpll_288m>,<&CLK_upll_480m_div2>,<&CLK_mpll_432m_div2>,<&CLK_mpll_345m_div2>,<&CLK_mpll_288m_div2>,<&CLK_mpll_432m_div8>,<&CLK_xtali_12m>;
    reg = <REG_CKG_BIST_VHE3_GP_BASE 0x4>;
    mux-shift = <2>;  //2+REG_CKG_BIST_VHE3_GP_OFFSET
    mux-width = <3>;
    gate-shift = <0>;  //0+REG_CKG_BIST_VHE3_GP_OFFSET
    auto-enable = <0>;
};

CLK_vhe3: CLK_vhe3 {
    #clock-cells = <0>;
    compatible = "sstar,composite-clock";
    clocks = <&CLK_ven_pll>,<&CLK_syspll_600m>,<&CLK_miupll_clk>,<&CLK_upll_480m>,<&CLK_mpll_432m>,<&CLK_upll_384m>,<&CLK_upll_320m>,<&CLK_mpll_288m>;
    reg = <REG_CKG_VHE3_BASE 0x4>;
    mux-shift = <2>;  //2+REG_CKG_VHE3_OFFSET
    mux-width = <3>;
    gate-shift = <0>;  //0+REG_CKG_VHE3_OFFSET
    auto-enable = <0>;
};

CLK_mfe3: CLK_mfe3 {
    #clock-cells = <0>;
    compatible = "sstar,composite-clock";
    clocks = <&CLK_ven_pll>,<&CLK_syspll_600m>,<&CLK_miupll_clk>,<&CLK_upll_480m>,<&CLK_mpll_432m>,<&CLK_upll_384m>,<&CLK_upll_320m>,<&CLK_mpll_288m>;
    reg = <REG_CKG_MFE3_BASE 0x4>;
    mux-shift = <2>;  //2+REG_CKG_MFE3_OFFSET
    mux-width = <3>;
    gate-shift = <0>;  //0+REG_CKG_MFE3_OFFSET
    auto-enable = <0>;
};

CLK_ven3_axi: CLK_ven3_axi {
    #clock-cells = <0>;
    compatible = "sstar,composite-clock";
    clocks = <&CLK_ven_pll>,<&CLK_syspll_600m>,<&CLK_miupll_clk>,<&CLK_upll_480m>,<&CLK_mpll_432m>,<&CLK_upll_384m>,<&CLK_upll_320m>,<&CLK_mpll_288m>;
    reg = <REG_CKG_VEN3_AXI_BASE 0x4>;
    mux-shift = <2>;  //2+REG_CKG_VEN3_AXI_OFFSET
    mux-width = <3>;
    gate-shift = <0>;  //0+REG_CKG_VEN3_AXI_OFFSET
    auto-enable = <0>;
};

CLK_bist_dsp_gp: CLK_bist_dsp_gp {
    #clock-cells = <0>;
    compatible = "sstar,composite-clock";
    clocks = <&CLK_upll_320m>,<&CLK_mpll_288m>,<&CLK_upll_480m_div2>,<&CLK_mpll_432m_div2>,<&CLK_mpll_345m_div2>,<&CLK_mpll_288m_div2>,<&CLK_mpll_432m_div8>,<&CLK_xtali_12m>;
    reg = <REG_CKG_BIST_DSP_GP_BASE 0x4>;
    mux-shift = <2>;  //2+REG_CKG_BIST_DSP_GP_OFFSET
    mux-width = <3>;
    gate-shift = <0>;  //0+REG_CKG_BIST_DSP_GP_OFFSET
    auto-enable = <0>;
};

CLK_dsp: CLK_dsp {
    #clock-cells = <0>;
    compatible = "sstar,composite-clock";
    clocks = <&CLK_syspll_600m>,<&CLK_miupll_clk>,<&CLK_upll_480m>,<&CLK_mpll_432m>;
    reg = <REG_CKG_DSP_BASE 0x4>;
    mux-shift = <2>;  //2+REG_CKG_DSP_OFFSET
    mux-width = <2>;
    gate-shift = <0>;  //0+REG_CKG_DSP_OFFSET
    auto-enable = <0>;
};

CLK_xtali_sc_gp: CLK_xtali_sc_gp {
    #clock-cells = <0>;
    compatible = "sstar,composite-clock";
    clocks = <&CLK_xtali_12m>,<&CLK_VOID>,<&CLK_VOID>,<&CLK_VOID>;
    reg = <REG_CKG_XTALI_SC_GP_BASE 0x4>;
    mux-shift = <6>;  //2+REG_CKG_XTALI_SC_GP_OFFSET
    mux-width = <2>;
    gate-shift = <4>;  //0+REG_CKG_XTALI_SC_GP_OFFSET
    auto-enable = <1>;
};

CLK_bist_sc_gp: CLK_bist_sc_gp {
    #clock-cells = <0>;
    compatible = "sstar,composite-clock";
    clocks = <&CLK_upll_320m>,<&CLK_mpll_288m>,<&CLK_upll_480m_div2>,<&CLK_mpll_432m_div2>,<&CLK_mpll_345m_div2>,<&CLK_mpll_288m_div2>,<&CLK_mpll_432m_div8>,<&CLK_xtali_12m>;
    reg = <REG_CKG_BIST_SC_GP_BASE 0x4>;
    mux-shift = <2>;  //2+REG_CKG_BIST_SC_GP_OFFSET
    mux-width = <3>;
    gate-shift = <0>;  //0+REG_CKG_BIST_SC_GP_OFFSET
    auto-enable = <0>;
};

CLK_jpe: CLK_jpe {
    #clock-cells = <0>;
    compatible = "sstar,composite-clock";
    clocks = <&CLK_upll_480m>,<&CLK_mpll_432m>,<&CLK_upll_384m>,<&CLK_upll_320m>,<&CLK_mpll_288m>,<&CLK_mpll_432m_div2>,<&CLK_VOID>,<&CLK_VOID>;
    reg = <REG_CKG_JPE_BASE 0x4>;
    mux-shift = <2>;  //2+REG_CKG_JPE_OFFSET
    mux-width = <3>;
    gate-shift = <0>;  //0+REG_CKG_JPE_OFFSET
    auto-enable = <0>;
};

CLK_jpe1: CLK_jpe1 {
    #clock-cells = <0>;
    compatible = "sstar,composite-clock";
    clocks = <&CLK_upll_480m>,<&CLK_mpll_432m>,<&CLK_upll_384m>,<&CLK_upll_320m>,<&CLK_mpll_288m>,<&CLK_mpll_432m_div2>,<&CLK_VOID>,<&CLK_VOID>;
    reg = <REG_CKG_JPE1_BASE 0x4>;
    mux-shift = <2>;  //2+REG_CKG_JPE1_OFFSET
    mux-width = <3>;
    gate-shift = <0>;  //0+REG_CKG_JPE1_OFFSET
    auto-enable = <0>;
};

CLK_aesdma: CLK_aesdma {
    #clock-cells = <0>;
    compatible = "sstar,composite-clock";
    clocks = <&CLK_mpll_576m>,<&CLK_mpll_288m>,<&CLK_mpll_345m_div2>,<&CLK_xtali_12m>;
    reg = <REG_CKG_AESDMA_BASE 0x4>;
    mux-shift = <2>;  //2+REG_CKG_AESDMA_OFFSET
    mux-width = <2>;
    gate-shift = <0>;  //0+REG_CKG_AESDMA_OFFSET
    glitch-shift = <4>;  //4+REG_CKG_AESDMA_OFFSET
    auto-enable = <0>;
};

CLK_sdio: CLK_sdio {
    #clock-cells = <0>;
    compatible = "sstar,composite-clock";
    clocks = <&CLK_upll_384m_div8>,<&CLK_mpll_86m_div2>,<&CLK_upll_320m_div8>,<&CLK_mpll_288m_div8>,<&CLK_upll_320m_div10>,<&CLK_upll_320m_div16>,<&CLK_xtali_12m>,<&CLK_xtali_12m_div40>,<&CLK_spi_synth_pll>,<&CLK_mpll_432m>,<&CLK_upll_384m>,<&CLK_upll_320m>,<&CLK_mpll_288m>,<&CLK_mpll_432m_div2>,<&CLK_mpll_432m_div4>,<&CLK_mpll_86m>;
    reg = <REG_CKG_SDIO_BASE 0x4>;
    mux-shift = <2>;  //2+REG_CKG_SDIO_OFFSET
    mux-width = <4>;
    gate-shift = <0>;  //0+REG_CKG_SDIO_OFFSET
    auto-enable = <0>;
};

CLK_sdio2: CLK_sdio2 {
    #clock-cells = <0>;
    compatible = "sstar,composite-clock";
    clocks = <&CLK_upll_384m_div8>,<&CLK_mpll_86m_div2>,<&CLK_upll_320m_div8>,<&CLK_mpll_288m_div8>,<&CLK_upll_320m_div10>,<&CLK_upll_320m_div16>,<&CLK_xtali_12m>,<&CLK_xtali_12m_div40>,<&CLK_spi_synth_pll>,<&CLK_mpll_432m>,<&CLK_upll_384m>,<&CLK_upll_320m>,<&CLK_mpll_288m>,<&CLK_mpll_432m_div2>,<&CLK_mpll_432m_div4>,<&CLK_mpll_86m>;
    reg = <REG_CKG_SDIO2_BASE 0x4>;
    mux-shift = <2>;  //2+REG_CKG_SDIO2_OFFSET
    mux-width = <4>;
    gate-shift = <0>;  //0+REG_CKG_SDIO2_OFFSET
    auto-enable = <0>;
};

CLK_sdio3: CLK_sdio3 {
    #clock-cells = <0>;
    compatible = "sstar,composite-clock";
    clocks = <&CLK_upll_384m_div8>,<&CLK_mpll_86m_div2>,<&CLK_upll_320m_div8>,<&CLK_mpll_288m_div8>,<&CLK_upll_320m_div10>,<&CLK_upll_320m_div16>,<&CLK_xtali_12m>,<&CLK_xtali_12m_div40>,<&CLK_spi_synth_pll>,<&CLK_mpll_432m>,<&CLK_upll_384m>,<&CLK_upll_320m>,<&CLK_mpll_288m>,<&CLK_mpll_432m_div2>,<&CLK_mpll_432m_div4>,<&CLK_mpll_86m>;
    reg = <REG_CKG_SDIO3_BASE 0x4>;
    mux-shift = <2>;  //2+REG_CKG_SDIO3_OFFSET
    mux-width = <4>;
    gate-shift = <0>;  //0+REG_CKG_SDIO3_OFFSET
    auto-enable = <0>;
};

CLK_sd: CLK_sd {
    #clock-cells = <0>;
    compatible = "sstar,composite-clock";
    clocks = <&CLK_upll_384m_div8>,<&CLK_mpll_86m_div2>,<&CLK_upll_320m_div8>,<&CLK_mpll_288m_div8>,<&CLK_upll_320m_div10>,<&CLK_upll_320m_div16>,<&CLK_xtali_12m>,<&CLK_xtali_12m_div40>,<&CLK_spi_synth_pll>,<&CLK_mpll_432m>,<&CLK_upll_384m>,<&CLK_upll_320m>,<&CLK_mpll_288m>,<&CLK_mpll_432m_div2>,<&CLK_sd_1x_p>,<&CLK_sd_2x_p>;
    reg = <REG_CKG_SD_BASE 0x4>;
    mux-shift = <2>;  //2+REG_CKG_SD_OFFSET
    mux-width = <4>;
    gate-shift = <0>;  //0+REG_CKG_SD_OFFSET
    auto-enable = <0>;
};

CLK_sd_syn: CLK_sd_syn {
    #clock-cells = <0>;
    compatible = "sstar,composite-clock";
    clocks = <&CLK_mpll_432m_div2>,<&CLK_mpll_432m>,<&CLK_xtali_12m>,<&CLK_VOID>;
    reg = <REG_CKG_SD_SYN_BASE 0x4>;
    mux-shift = <10>;  //2+REG_CKG_SD_SYN_OFFSET
    mux-width = <2>;
    gate-shift = <8>;  //0+REG_CKG_SD_SYN_OFFSET
    glitch-shift = <12>;  //4+REG_CKG_SD_SYN_OFFSET
    auto-enable = <0>;
};

CLK_bist_isp_gp: CLK_bist_isp_gp {
    #clock-cells = <0>;
    compatible = "sstar,composite-clock";
    clocks = <&CLK_upll_320m>,<&CLK_mpll_288m>,<&CLK_upll_480m_div2>,<&CLK_mpll_432m_div2>,<&CLK_mpll_345m_div2>,<&CLK_mpll_288m_div2>,<&CLK_mpll_432m_div8>,<&CLK_xtali_12m>;
    reg = <REG_CKG_BIST_ISP_GP_BASE 0x4>;
    mux-shift = <7>;  //2+REG_CKG_BIST_ISP_GP_OFFSET
    mux-width = <3>;
    gate-shift = <5>;  //0+REG_CKG_BIST_ISP_GP_OFFSET
    auto-enable = <0>;
};

CLK_isp: CLK_isp {
    #clock-cells = <0>;
    compatible = "sstar,composite-clock";
    clocks = <&CLK_isppll_clk>,<&CLK_miupll_clk>,<&CLK_upll_480m>,<&CLK_mpll_432m>,<&CLK_upll_384m>,<&CLK_upll_320m>,<&CLK_upll_480m_div2>,<&CLK_syspll_600m>;
    reg = <REG_CKG_ISP_BASE 0x4>;
    mux-shift = <10>;  //2+REG_CKG_ISP_OFFSET
    mux-width = <3>;
    gate-shift = <8>;  //0+REG_CKG_ISP_OFFSET
    auto-enable = <0>;
};

CLK_bist_isp1_gp: CLK_bist_isp1_gp {
    #clock-cells = <0>;
    compatible = "sstar,composite-clock";
    clocks = <&CLK_upll_320m>,<&CLK_mpll_288m>,<&CLK_upll_480m_div2>,<&CLK_mpll_432m_div2>,<&CLK_mpll_345m_div2>,<&CLK_mpll_288m_div2>,<&CLK_mpll_432m_div8>,<&CLK_xtali_12m>;
    reg = <REG_CKG_BIST_ISP1_GP_BASE 0x4>;
    mux-shift = <2>;  //2+REG_CKG_BIST_ISP1_GP_OFFSET
    mux-width = <3>;
    gate-shift = <0>;  //0+REG_CKG_BIST_ISP1_GP_OFFSET
    auto-enable = <0>;
};

CLK_isp1: CLK_isp1 {
    #clock-cells = <0>;
    compatible = "sstar,composite-clock";
    clocks = <&CLK_isppll_clk>,<&CLK_miupll_clk>,<&CLK_upll_480m>,<&CLK_mpll_432m>,<&CLK_upll_384m>,<&CLK_upll_320m>,<&CLK_upll_480m_div2>,<&CLK_syspll_600m>;
    reg = <REG_CKG_ISP1_BASE 0x4>;
    mux-shift = <2>;  //2+REG_CKG_ISP1_OFFSET
    mux-width = <3>;
    gate-shift = <0>;  //0+REG_CKG_ISP1_OFFSET
    auto-enable = <0>;
};

CLK_fclk1: CLK_fclk1 {
    #clock-cells = <0>;
    compatible = "sstar,composite-clock";
    clocks = <&CLK_isppll_clk>,<&CLK_miupll_clk>,<&CLK_upll_480m>,<&CLK_mpll_432m>,<&CLK_upll_384m>,<&CLK_upll_320m>,<&CLK_upll_480m_div2>,<&CLK_syspll_600m>;
    reg = <REG_CKG_FCLK1_BASE 0x4>;
    mux-shift = <2>;  //2+REG_CKG_FCLK1_OFFSET
    mux-width = <3>;
    gate-shift = <0>;  //0+REG_CKG_FCLK1_OFFSET
    auto-enable = <0>;
};

CLK_mop0: CLK_mop0 {
    #clock-cells = <0>;
    compatible = "sstar,composite-clock";
    clocks = <&CLK_upll_384m>,<&CLK_mpll_432m>,<&CLK_upll_480m>,<&CLK_upll_320m>,<&CLK_mpll_288m>,<&CLK_upll_480m_div2>,<&CLK_mpll_432m_div2>,<&CLK_upll_384m_div2>;
    reg = <REG_CKG_MOP0_BASE 0x4>;
    mux-shift = <2>;  //2+REG_CKG_MOP0_OFFSET
    mux-width = <3>;
    gate-shift = <0>;  //0+REG_CKG_MOP0_OFFSET
    auto-enable = <0>;
};

CLK_mop1: CLK_mop1 {
    #clock-cells = <0>;
    compatible = "sstar,composite-clock";
    clocks = <&CLK_upll_384m>,<&CLK_mpll_432m>,<&CLK_upll_480m>,<&CLK_upll_320m>,<&CLK_mpll_288m>,<&CLK_upll_480m_div2>,<&CLK_mpll_432m_div2>,<&CLK_upll_384m_div2>;
    reg = <REG_CKG_MOP1_BASE 0x4>;
    mux-shift = <10>;  //2+REG_CKG_MOP1_OFFSET
    mux-width = <3>;
    gate-shift = <8>;  //0+REG_CKG_MOP1_OFFSET
    auto-enable = <0>;
};

CLK_mop2: CLK_mop2 {
    #clock-cells = <0>;
    compatible = "sstar,composite-clock";
    clocks = <&CLK_upll_384m>,<&CLK_mpll_432m>,<&CLK_upll_480m>,<&CLK_upll_320m>,<&CLK_mpll_288m>,<&CLK_upll_480m_div2>,<&CLK_mpll_432m_div2>,<&CLK_upll_384m_div2>;
    reg = <REG_CKG_MOP2_BASE 0x4>;
    mux-shift = <2>;  //2+REG_CKG_MOP2_OFFSET
    mux-width = <3>;
    gate-shift = <0>;  //0+REG_CKG_MOP2_OFFSET
    auto-enable = <0>;
};

CLK_disp_432: CLK_disp_432 {
    #clock-cells = <0>;
    compatible = "sstar,composite-clock";
    clocks = <&CLK_mpll_432m>,<&CLK_VOID>,<&CLK_VOID>,<&CLK_VOID>;
    reg = <REG_CKG_DISP_432_BASE 0x4>;
    mux-shift = <10>;  //2+REG_CKG_DISP_432_OFFSET
    mux-width = <2>;
    gate-shift = <8>;  //0+REG_CKG_DISP_432_OFFSET
    auto-enable = <0>;
};

CLK_disp_216: CLK_disp_216 {
    #clock-cells = <0>;
    compatible = "sstar,composite-clock";
    clocks = <&CLK_mpll_432m_div2>,<&CLK_VOID>,<&CLK_VOID>,<&CLK_VOID>;
    reg = <REG_CKG_DISP_216_BASE 0x4>;
    mux-shift = <14>;  //2+REG_CKG_DISP_216_OFFSET
    mux-width = <2>;
    gate-shift = <12>;  //0+REG_CKG_DISP_216_OFFSET
    auto-enable = <0>;
};

CLK_disp_pixel_0: CLK_disp_pixel_0 {
    #clock-cells = <0>;
    compatible = "sstar,composite-clock";
    clocks = <&CLK_mpll_288m>,<&CLK_upll_320m>,<&CLK_upll_384m_div2>,<&CLK_upll_480m_div2>,<&CLK_mpll_432m_div2>,<&CLK_mpll_345m_div2>,<&CLK_mpll_246m_div2>,<&CLK_mpll_288m_div2>,<&CLK_mpll_432m_div4>,<&CLK_lpll_clk>,<&CLK_disppll_clk>,<&CLK_lpll_clk_div2>,<&CLK_lpll_clk_div4>,<&CLK_disppll_clk_div2>,<&CLK_disppll_clk_div4>,<&CLK_VOID>;
    reg = <REG_CKG_DISP_PIXEL_0_BASE 0x4>;
    mux-shift = <2>;  //2+REG_CKG_DISP_PIXEL_0_OFFSET
    mux-width = <4>;
    gate-shift = <0>;  //0+REG_CKG_DISP_PIXEL_0_OFFSET
    auto-enable = <0>;
};

CLK_disp_pixel_1: CLK_disp_pixel_1 {
    #clock-cells = <0>;
    compatible = "sstar,composite-clock";
    clocks = <&CLK_mpll_288m>,<&CLK_upll_320m>,<&CLK_upll_384m_div2>,<&CLK_upll_480m_div2>,<&CLK_mpll_432m_div2>,<&CLK_mpll_345m_div2>,<&CLK_mpll_246m_div2>,<&CLK_mpll_288m_div2>,<&CLK_mpll_432m_div4>,<&CLK_lpll_clk>,<&CLK_disppll_clk>,<&CLK_lpll_clk_div2>,<&CLK_lpll_clk_div4>,<&CLK_disppll_clk_div2>,<&CLK_disppll_clk_div4>,<&CLK_VOID>;
    reg = <REG_CKG_DISP_PIXEL_1_BASE 0x4>;
    mux-shift = <10>;  //2+REG_CKG_DISP_PIXEL_1_OFFSET
    mux-width = <4>;
    gate-shift = <8>;  //0+REG_CKG_DISP_PIXEL_1_OFFSET
    auto-enable = <0>;
};

CLK_disp_pixel_2: CLK_disp_pixel_2 {
    #clock-cells = <0>;
    compatible = "sstar,composite-clock";
    clocks = <&CLK_mpll_288m>,<&CLK_upll_320m>,<&CLK_upll_384m_div2>,<&CLK_upll_480m_div2>,<&CLK_mpll_432m_div2>,<&CLK_mpll_345m_div2>,<&CLK_mpll_246m_div2>,<&CLK_mpll_288m_div2>,<&CLK_mpll_432m_div4>,<&CLK_lpll_clk>,<&CLK_disppll_clk>,<&CLK_lpll_clk_div2>,<&CLK_lpll_clk_div4>,<&CLK_disppll_clk_div2>,<&CLK_disppll_clk_div4>,<&CLK_VOID>;
    reg = <REG_CKG_DISP_PIXEL_2_BASE 0x4>;
    mux-shift = <2>;  //2+REG_CKG_DISP_PIXEL_2_OFFSET
    mux-width = <4>;
    gate-shift = <0>;  //0+REG_CKG_DISP_PIXEL_2_OFFSET
    auto-enable = <0>;
};

CLK_jpd: CLK_jpd {
    #clock-cells = <0>;
    compatible = "sstar,composite-clock";
    clocks = <&CLK_syspll_600m>,<&CLK_miupll_clk>,<&CLK_upll_480m>,<&CLK_mpll_432m>,<&CLK_upll_384m>,<&CLK_mpll_288m>,<&CLK_VOID>,<&CLK_VOID>;
    reg = <REG_CKG_JPD_BASE 0x4>;
    mux-shift = <2>;  //2+REG_CKG_JPD_OFFSET
    mux-width = <3>;
    gate-shift = <0>;  //0+REG_CKG_JPD_OFFSET
    auto-enable = <0>;
};

CLK_jpd1: CLK_jpd1 {
    #clock-cells = <0>;
    compatible = "sstar,composite-clock";
    clocks = <&CLK_syspll_600m>,<&CLK_miupll_clk>,<&CLK_upll_480m>,<&CLK_mpll_432m>,<&CLK_upll_384m>,<&CLK_mpll_288m>,<&CLK_VOID>,<&CLK_VOID>;
    reg = <REG_CKG_JPD1_BASE 0x4>;
    mux-shift = <2>;  //2+REG_CKG_JPD1_OFFSET
    mux-width = <3>;
    gate-shift = <0>;  //0+REG_CKG_JPD1_OFFSET
    auto-enable = <0>;
};

CLK_jpd2: CLK_jpd2 {
    #clock-cells = <0>;
    compatible = "sstar,composite-clock";
    clocks = <&CLK_syspll_600m>,<&CLK_miupll_clk>,<&CLK_upll_480m>,<&CLK_mpll_432m>,<&CLK_upll_384m>,<&CLK_mpll_288m>,<&CLK_VOID>,<&CLK_VOID>;
    reg = <REG_CKG_JPD2_BASE 0x4>;
    mux-shift = <2>;  //2+REG_CKG_JPD2_OFFSET
    mux-width = <3>;
    gate-shift = <0>;  //0+REG_CKG_JPD2_OFFSET
    auto-enable = <0>;
};

CLK_jpd3: CLK_jpd3 {
    #clock-cells = <0>;
    compatible = "sstar,composite-clock";
    clocks = <&CLK_syspll_600m>,<&CLK_miupll_clk>,<&CLK_upll_480m>,<&CLK_mpll_432m>,<&CLK_upll_384m>,<&CLK_mpll_288m>,<&CLK_VOID>,<&CLK_VOID>;
    reg = <REG_CKG_JPD3_BASE 0x4>;
    mux-shift = <2>;  //2+REG_CKG_JPD3_OFFSET
    mux-width = <3>;
    gate-shift = <0>;  //0+REG_CKG_JPD3_OFFSET
    auto-enable = <0>;
};

CLK_bist_disp_gp: CLK_bist_disp_gp {
    #clock-cells = <0>;
    compatible = "sstar,composite-clock";
    clocks = <&CLK_upll_320m>,<&CLK_mpll_288m>,<&CLK_upll_480m_div2>,<&CLK_mpll_432m_div2>,<&CLK_mpll_345m_div2>,<&CLK_mpll_288m_div2>,<&CLK_mpll_432m_div8>,<&CLK_xtali_12m>;
    reg = <REG_CKG_BIST_DISP_GP_BASE 0x4>;
    mux-shift = <2>;  //2+REG_CKG_BIST_DISP_GP_OFFSET
    mux-width = <3>;
    gate-shift = <0>;  //0+REG_CKG_BIST_DISP_GP_OFFSET
    auto-enable = <0>;
};

CLK_ive: CLK_ive {
    #clock-cells = <0>;
    compatible = "sstar,composite-clock";
    clocks = <&CLK_mpll_432m_div2>,<&CLK_mpll_345m_div2>,<&CLK_upll_480m>,<&CLK_mpll_246m_div2>,<&CLK_mpll_288m>,<&CLK_upll_320m>,<&CLK_upll_384m>,<&CLK_upll_480m_div2>;
    reg = <REG_CKG_IVE_BASE 0x4>;
    mux-shift = <10>;  //2+REG_CKG_IVE_OFFSET
    mux-width = <3>;
    gate-shift = <8>;  //0+REG_CKG_IVE_OFFSET
    auto-enable = <0>;
};

CLK_ge: CLK_ge {
    #clock-cells = <0>;
    compatible = "sstar,composite-clock";
    clocks = <&CLK_syspll_600m>,<&CLK_upll_480m>,<&CLK_upll_320m>,<&CLK_upll_480m_div2>,<&CLK_miu_p>,<&CLK_VOID>,<&CLK_VOID>,<&CLK_VOID>;
    reg = <REG_CKG_GE_BASE 0x4>;
    mux-shift = <2>;  //2+REG_CKG_GE_OFFSET
    mux-width = <3>;
    gate-shift = <0>;  //0+REG_CKG_GE_OFFSET
    auto-enable = <0>;
};

CLK_ge2: CLK_ge2 {
    #clock-cells = <0>;
    compatible = "sstar,composite-clock";
    clocks = <&CLK_syspll_600m>,<&CLK_upll_480m>,<&CLK_upll_320m>,<&CLK_upll_480m_div2>,<&CLK_miu_p>,<&CLK_VOID>,<&CLK_VOID>,<&CLK_VOID>;
    reg = <REG_CKG_GE2_BASE 0x4>;
    mux-shift = <2>;  //2+REG_CKG_GE2_OFFSET
    mux-width = <3>;
    gate-shift = <0>;  //0+REG_CKG_GE2_OFFSET
    auto-enable = <0>;
};

CLK_ldcfeye: CLK_ldcfeye {
    #clock-cells = <0>;
    compatible = "sstar,composite-clock";
    clocks = <&CLK_syspll_600m>,<&CLK_upll_480m>,<&CLK_mpll_432m>,<&CLK_upll_384m>,<&CLK_upll_320m>,<&CLK_mpll_288m>,<&CLK_mpll_432m_div2>,<&CLK_mpll_246m>;
    reg = <REG_CKG_LDCFEYE_BASE 0x4>;
    mux-shift = <2>;  //2+REG_CKG_LDCFEYE_OFFSET
    mux-width = <3>;
    gate-shift = <0>;  //0+REG_CKG_LDCFEYE_OFFSET
    auto-enable = <0>;
};

CLK_ldcfeye2: CLK_ldcfeye2 {
    #clock-cells = <0>;
    compatible = "sstar,composite-clock";
    clocks = <&CLK_syspll_600m>,<&CLK_upll_480m>,<&CLK_mpll_432m>,<&CLK_upll_384m>,<&CLK_upll_320m>,<&CLK_mpll_288m>,<&CLK_mpll_432m_div2>,<&CLK_mpll_246m>;
    reg = <REG_CKG_LDCFEYE2_BASE 0x4>;
    mux-shift = <2>;  //2+REG_CKG_LDCFEYE2_OFFSET
    mux-width = <3>;
    gate-shift = <0>;  //0+REG_CKG_LDCFEYE2_OFFSET
    auto-enable = <0>;
};

CLK_bist_net_gp: CLK_bist_net_gp {
    #clock-cells = <0>;
    compatible = "sstar,composite-clock";
    clocks = <&CLK_upll_320m>,<&CLK_mpll_288m>,<&CLK_upll_480m_div2>,<&CLK_mpll_432m_div2>,<&CLK_mpll_345m_div2>,<&CLK_mpll_288m_div2>,<&CLK_mpll_432m_div8>,<&CLK_xtali_12m>;
    reg = <REG_CKG_BIST_NET_GP_BASE 0x4>;
    mux-shift = <2>;  //2+REG_CKG_BIST_NET_GP_OFFSET
    mux-width = <3>;
    gate-shift = <0>;  //0+REG_CKG_BIST_NET_GP_OFFSET
    auto-enable = <0>;
};

CLK_gmac0_gmii: CLK_gmac0_gmii {
    #clock-cells = <0>;
    compatible = "sstar,composite-clock";
    clocks = <&CLK_gmacpll_250_div2>,<&CLK_gmacpll_250_div10>,<&CLK_gmacpll_250_div100>,<&CLK_gmac0_external_ref_buf>;
    reg = <REG_CKG_GMAC0_GMII_BASE 0x4>;
    mux-shift = <2>;  //2+REG_CKG_GMAC0_GMII_OFFSET
    mux-width = <2>;
    gate-shift = <0>;  //0+REG_CKG_GMAC0_GMII_OFFSET
    auto-enable = <0>;
};

CLK_gmac1_gmii: CLK_gmac1_gmii {
    #clock-cells = <0>;
    compatible = "sstar,composite-clock";
    clocks = <&CLK_gmacpll_250_div2>,<&CLK_gmacpll_250_div10>,<&CLK_gmacpll_250_div100>,<&CLK_gmac1_external_ref_buf>;
    reg = <REG_CKG_GMAC1_GMII_BASE 0x4>;
    mux-shift = <2>;  //2+REG_CKG_GMAC1_GMII_OFFSET
    mux-width = <2>;
    gate-shift = <0>;  //0+REG_CKG_GMAC1_GMII_OFFSET
    auto-enable = <0>;
};

CLK_bist_pcie0_gp: CLK_bist_pcie0_gp {
    #clock-cells = <0>;
    compatible = "sstar,composite-clock";
    clocks = <&CLK_upll_320m>,<&CLK_mpll_288m>,<&CLK_upll_480m_div2>,<&CLK_mpll_432m_div2>,<&CLK_mpll_345m_div2>,<&CLK_mpll_288m_div2>,<&CLK_mpll_432m_div8>,<&CLK_xtali_12m>;
    reg = <REG_CKG_BIST_PCIE0_GP_BASE 0x4>;
    mux-shift = <2>;  //2+REG_CKG_BIST_PCIE0_GP_OFFSET
    mux-width = <3>;
    gate-shift = <0>;  //0+REG_CKG_BIST_PCIE0_GP_OFFSET
    auto-enable = <0>;
};

CLK_pcie0_slv_aclk: CLK_pcie0_slv_aclk {
    #clock-cells = <0>;
    compatible = "sstar,composite-clock";
    clocks = <&CLK_mpll_432m>,<&CLK_upll_384m>,<&CLK_upll_320m>,<&CLK_mpll_288m>,<&CLK_upll_384m_div2>,<&CLK_VOID>,<&CLK_VOID>,<&CLK_VOID>;
    reg = <REG_CKG_PCIE0_SLV_ACLK_BASE 0x4>;
    mux-shift = <2>;  //2+REG_CKG_PCIE0_SLV_ACLK_OFFSET
    mux-width = <3>;
    gate-shift = <0>;  //0+REG_CKG_PCIE0_SLV_ACLK_OFFSET
    auto-enable = <0>;
};

CLK_pcie0_ref_alt: CLK_pcie0_ref_alt {
    #clock-cells = <0>;
    compatible = "sstar,composite-clock";
    clocks = <&CLK_syspll_400m_div4>,<&CLK_VOID>,<&CLK_VOID>,<&CLK_VOID>;
    reg = <REG_CKG_PCIE0_REF_ALT_BASE 0x4>;
    mux-shift = <2>;  //2+REG_CKG_PCIE0_REF_ALT_OFFSET
    mux-width = <2>;
    gate-shift = <0>;  //0+REG_CKG_PCIE0_REF_ALT_OFFSET
    auto-enable = <0>;
};

CLK_pcie0_jtg: CLK_pcie0_jtg {
    #clock-cells = <0>;
    compatible = "sstar,composite-clock";
    clocks = <&CLK_syspll_400m_div8>,<&CLK_VOID>,<&CLK_VOID>,<&CLK_VOID>;
    reg = <REG_CKG_PCIE0_JTG_BASE 0x4>;
    mux-shift = <2>;  //2+REG_CKG_PCIE0_JTG_OFFSET
    mux-width = <2>;
    gate-shift = <0>;  //0+REG_CKG_PCIE0_JTG_OFFSET
    auto-enable = <0>;
};

CLK_pcie0_bs: CLK_pcie0_bs {
    #clock-cells = <0>;
    compatible = "sstar,composite-clock";
    clocks = <&CLK_syspll_400m_div8>,<&CLK_VOID>,<&CLK_VOID>,<&CLK_VOID>;
    reg = <REG_CKG_PCIE0_BS_BASE 0x4>;
    mux-shift = <2>;  //2+REG_CKG_PCIE0_BS_OFFSET
    mux-width = <2>;
    gate-shift = <0>;  //0+REG_CKG_PCIE0_BS_OFFSET
    auto-enable = <0>;
};

CLK_pcie0: CLK_pcie0 {
    #clock-cells = <0>;
    compatible = "sstar,composite-clock";
    clocks = <&CLK_mpll_432m>,<&CLK_upll_384m>,<&CLK_mpll_345m>,<&CLK_mpll_288m>;
    reg = <REG_CKG_PCIE0_BASE 0x4>;
    mux-shift = <2>;  //2+REG_CKG_PCIE0_OFFSET
    mux-width = <2>;
    gate-shift = <0>;  //0+REG_CKG_PCIE0_OFFSET
    auto-enable = <0>;
};

CLK_bist_pcie1_gp: CLK_bist_pcie1_gp {
    #clock-cells = <0>;
    compatible = "sstar,composite-clock";
    clocks = <&CLK_upll_320m>,<&CLK_mpll_288m>,<&CLK_upll_480m_div2>,<&CLK_mpll_432m_div2>,<&CLK_mpll_345m_div2>,<&CLK_mpll_288m_div2>,<&CLK_mpll_432m_div8>,<&CLK_xtali_12m>;
    reg = <REG_CKG_BIST_PCIE1_GP_BASE 0x4>;
    mux-shift = <2>;  //2+REG_CKG_BIST_PCIE1_GP_OFFSET
    mux-width = <3>;
    gate-shift = <0>;  //0+REG_CKG_BIST_PCIE1_GP_OFFSET
    auto-enable = <0>;
};

CLK_pcie1_slv_aclk: CLK_pcie1_slv_aclk {
    #clock-cells = <0>;
    compatible = "sstar,composite-clock";
    clocks = <&CLK_mpll_432m>,<&CLK_upll_384m>,<&CLK_upll_320m>,<&CLK_mpll_288m>,<&CLK_upll_384m_div2>,<&CLK_VOID>,<&CLK_VOID>,<&CLK_VOID>;
    reg = <REG_CKG_PCIE1_SLV_ACLK_BASE 0x4>;
    mux-shift = <2>;  //2+REG_CKG_PCIE1_SLV_ACLK_OFFSET
    mux-width = <3>;
    gate-shift = <0>;  //0+REG_CKG_PCIE1_SLV_ACLK_OFFSET
    auto-enable = <0>;
};

CLK_pcie1_ref_alt: CLK_pcie1_ref_alt {
    #clock-cells = <0>;
    compatible = "sstar,composite-clock";
    clocks = <&CLK_syspll_400m_div4>,<&CLK_VOID>,<&CLK_VOID>,<&CLK_VOID>;
    reg = <REG_CKG_PCIE1_REF_ALT_BASE 0x4>;
    mux-shift = <2>;  //2+REG_CKG_PCIE1_REF_ALT_OFFSET
    mux-width = <2>;
    gate-shift = <0>;  //0+REG_CKG_PCIE1_REF_ALT_OFFSET
    auto-enable = <0>;
};

CLK_pcie1_jtg: CLK_pcie1_jtg {
    #clock-cells = <0>;
    compatible = "sstar,composite-clock";
    clocks = <&CLK_syspll_400m_div8>,<&CLK_VOID>,<&CLK_VOID>,<&CLK_VOID>;
    reg = <REG_CKG_PCIE1_JTG_BASE 0x4>;
    mux-shift = <2>;  //2+REG_CKG_PCIE1_JTG_OFFSET
    mux-width = <2>;
    gate-shift = <0>;  //0+REG_CKG_PCIE1_JTG_OFFSET
    auto-enable = <0>;
};

CLK_pcie1_bs: CLK_pcie1_bs {
    #clock-cells = <0>;
    compatible = "sstar,composite-clock";
    clocks = <&CLK_syspll_400m_div8>,<&CLK_VOID>,<&CLK_VOID>,<&CLK_VOID>;
    reg = <REG_CKG_PCIE1_BS_BASE 0x4>;
    mux-shift = <2>;  //2+REG_CKG_PCIE1_BS_OFFSET
    mux-width = <2>;
    gate-shift = <0>;  //0+REG_CKG_PCIE1_BS_OFFSET
    auto-enable = <0>;
};

CLK_pcie1: CLK_pcie1 {
    #clock-cells = <0>;
    compatible = "sstar,composite-clock";
    clocks = <&CLK_mpll_432m>,<&CLK_upll_384m>,<&CLK_mpll_345m>,<&CLK_mpll_288m>;
    reg = <REG_CKG_PCIE1_BASE 0x4>;
    mux-shift = <2>;  //2+REG_CKG_PCIE1_OFFSET
    mux-width = <2>;
    gate-shift = <0>;  //0+REG_CKG_PCIE1_OFFSET
    auto-enable = <0>;
};

CLK_lvds_func_a0: CLK_lvds_func_a0 {
    #clock-cells = <0>;
    compatible = "sstar,composite-clock";
    clocks = <&CLK_mpll_432m_div2>,<&CLK_upll_480m_div2>,<&CLK_mpll_345m_div2>,<&CLK_mpll_288m_div2>,<&CLK_mpll_86m>,<&CLK_upll_320m_div8>,<&CLK_VOID>,<&CLK_VOID>;
    reg = <REG_CKG_LVDS_FUNC_A0_BASE 0x4>;
    mux-shift = <2>;  //2+REG_CKG_LVDS_FUNC_A0_OFFSET
    mux-width = <3>;
    gate-shift = <0>;  //0+REG_CKG_LVDS_FUNC_A0_OFFSET
    auto-enable = <0>;
};

CLK_lvds_func_a1: CLK_lvds_func_a1 {
    #clock-cells = <0>;
    compatible = "sstar,composite-clock";
    clocks = <&CLK_mpll_432m_div2>,<&CLK_upll_480m_div2>,<&CLK_mpll_345m_div2>,<&CLK_mpll_288m_div2>,<&CLK_mpll_86m>,<&CLK_upll_320m_div8>,<&CLK_VOID>,<&CLK_VOID>;
    reg = <REG_CKG_LVDS_FUNC_A1_BASE 0x4>;
    mux-shift = <2>;  //2+REG_CKG_LVDS_FUNC_A1_OFFSET
    mux-width = <3>;
    gate-shift = <0>;  //0+REG_CKG_LVDS_FUNC_A1_OFFSET
    auto-enable = <0>;
};

CLK_lvds_func_a2: CLK_lvds_func_a2 {
    #clock-cells = <0>;
    compatible = "sstar,composite-clock";
    clocks = <&CLK_mpll_432m_div2>,<&CLK_upll_480m_div2>,<&CLK_mpll_345m_div2>,<&CLK_mpll_288m_div2>,<&CLK_mpll_86m>,<&CLK_upll_320m_div8>,<&CLK_VOID>,<&CLK_VOID>;
    reg = <REG_CKG_LVDS_FUNC_A2_BASE 0x4>;
    mux-shift = <2>;  //2+REG_CKG_LVDS_FUNC_A2_OFFSET
    mux-width = <3>;
    gate-shift = <0>;  //0+REG_CKG_LVDS_FUNC_A2_OFFSET
    auto-enable = <0>;
};

CLK_lvds_func_a3: CLK_lvds_func_a3 {
    #clock-cells = <0>;
    compatible = "sstar,composite-clock";
    clocks = <&CLK_mpll_432m_div2>,<&CLK_upll_480m_div2>,<&CLK_mpll_345m_div2>,<&CLK_mpll_288m_div2>,<&CLK_mpll_86m>,<&CLK_upll_320m_div8>,<&CLK_VOID>,<&CLK_VOID>;
    reg = <REG_CKG_LVDS_FUNC_A3_BASE 0x4>;
    mux-shift = <2>;  //2+REG_CKG_LVDS_FUNC_A3_OFFSET
    mux-width = <3>;
    gate-shift = <0>;  //0+REG_CKG_LVDS_FUNC_A3_OFFSET
    auto-enable = <0>;
};

CLK_lvds_func_a4: CLK_lvds_func_a4 {
    #clock-cells = <0>;
    compatible = "sstar,composite-clock";
    clocks = <&CLK_mpll_432m_div2>,<&CLK_upll_480m_div2>,<&CLK_mpll_345m_div2>,<&CLK_mpll_288m_div2>,<&CLK_mpll_86m>,<&CLK_upll_320m_div8>,<&CLK_VOID>,<&CLK_VOID>;
    reg = <REG_CKG_LVDS_FUNC_A4_BASE 0x4>;
    mux-shift = <2>;  //2+REG_CKG_LVDS_FUNC_A4_OFFSET
    mux-width = <3>;
    gate-shift = <0>;  //0+REG_CKG_LVDS_FUNC_A4_OFFSET
    auto-enable = <0>;
};

CLK_lvds_func_a5: CLK_lvds_func_a5 {
    #clock-cells = <0>;
    compatible = "sstar,composite-clock";
    clocks = <&CLK_mpll_432m_div2>,<&CLK_upll_480m_div2>,<&CLK_mpll_345m_div2>,<&CLK_mpll_288m_div2>,<&CLK_mpll_86m>,<&CLK_upll_320m_div8>,<&CLK_VOID>,<&CLK_VOID>;
    reg = <REG_CKG_LVDS_FUNC_A5_BASE 0x4>;
    mux-shift = <2>;  //2+REG_CKG_LVDS_FUNC_A5_OFFSET
    mux-width = <3>;
    gate-shift = <0>;  //0+REG_CKG_LVDS_FUNC_A5_OFFSET
    auto-enable = <0>;
};

CLK_lvds_func_a6: CLK_lvds_func_a6 {
    #clock-cells = <0>;
    compatible = "sstar,composite-clock";
    clocks = <&CLK_mpll_432m_div2>,<&CLK_upll_480m_div2>,<&CLK_mpll_345m_div2>,<&CLK_mpll_288m_div2>,<&CLK_mpll_86m>,<&CLK_upll_320m_div8>,<&CLK_VOID>,<&CLK_VOID>;
    reg = <REG_CKG_LVDS_FUNC_A6_BASE 0x4>;
    mux-shift = <2>;  //2+REG_CKG_LVDS_FUNC_A6_OFFSET
    mux-width = <3>;
    gate-shift = <0>;  //0+REG_CKG_LVDS_FUNC_A6_OFFSET
    auto-enable = <0>;
};

CLK_lvds_func_a7: CLK_lvds_func_a7 {
    #clock-cells = <0>;
    compatible = "sstar,composite-clock";
    clocks = <&CLK_mpll_432m_div2>,<&CLK_upll_480m_div2>,<&CLK_mpll_345m_div2>,<&CLK_mpll_288m_div2>,<&CLK_mpll_86m>,<&CLK_upll_320m_div8>,<&CLK_VOID>,<&CLK_VOID>;
    reg = <REG_CKG_LVDS_FUNC_A7_BASE 0x4>;
    mux-shift = <2>;  //2+REG_CKG_LVDS_FUNC_A7_OFFSET
    mux-width = <3>;
    gate-shift = <0>;  //0+REG_CKG_LVDS_FUNC_A7_OFFSET
    auto-enable = <0>;
};

CLK_au_sys_384: CLK_au_sys_384 {
    #clock-cells = <0>;
    compatible = "sstar,composite-clock";
    clocks = <&CLK_syspll_600m>,<&CLK_mpll_576m>,<&CLK_upll_480m>,<&CLK_mpll_432m>,<&CLK_upll_384m>,<&CLK_VOID>,<&CLK_VOID>,<&CLK_VOID>;
    reg = <REG_CKG_AU_SYS_384_BASE 0x4>;
    mux-shift = <2>;  //2+REG_CKG_AU_SYS_384_OFFSET
    mux-width = <3>;
    gate-shift = <0>;  //0+REG_CKG_AU_SYS_384_OFFSET
    auto-enable = <0>;
};

CLK_au_sys_432: CLK_au_sys_432 {
    #clock-cells = <0>;
    compatible = "sstar,composite-clock";
    clocks = <&CLK_syspll_600m>,<&CLK_mpll_576m>,<&CLK_upll_480m>,<&CLK_mpll_432m>,<&CLK_upll_384m>,<&CLK_VOID>,<&CLK_VOID>,<&CLK_VOID>;
    reg = <REG_CKG_AU_SYS_432_BASE 0x4>;
    mux-shift = <2>;  //2+REG_CKG_AU_SYS_432_OFFSET
    mux-width = <3>;
    gate-shift = <0>;  //0+REG_CKG_AU_SYS_432_OFFSET
    auto-enable = <0>;
};

CLK_bist_miu0: CLK_bist_miu0 {
    #clock-cells = <0>;
    compatible = "sstar,composite-clock";
    clocks = <&CLK_upll_320m>,<&CLK_mpll_288m>,<&CLK_upll_480m_div2>,<&CLK_mpll_432m_div2>,<&CLK_mpll_345m_div2>,<&CLK_mpll_288m_div2>,<&CLK_mpll_432m_div8>,<&CLK_xtali_12m>;
    reg = <REG_CKG_BIST_MIU0_BASE 0x4>;
    mux-shift = <2>;  //2+REG_CKG_BIST_MIU0_OFFSET
    mux-width = <3>;
    gate-shift = <0>;  //0+REG_CKG_BIST_MIU0_OFFSET
    auto-enable = <0>;
};

CLK_bist_miu1: CLK_bist_miu1 {
    #clock-cells = <0>;
    compatible = "sstar,composite-clock";
    clocks = <&CLK_upll_320m>,<&CLK_mpll_288m>,<&CLK_upll_480m_div2>,<&CLK_mpll_432m_div2>,<&CLK_mpll_345m_div2>,<&CLK_mpll_288m_div2>,<&CLK_mpll_432m_div8>,<&CLK_xtali_12m>;
    reg = <REG_CKG_BIST_MIU1_BASE 0x4>;
    mux-shift = <2>;  //2+REG_CKG_BIST_MIU1_OFFSET
    mux-width = <3>;
    gate-shift = <0>;  //0+REG_CKG_BIST_MIU1_OFFSET
    auto-enable = <0>;
};

CLK_usb_phyd_200: CLK_usb_phyd_200 {
    #clock-cells = <0>;
    compatible = "sstar,composite-clock";
    clocks = <&CLK_syspll_400m_div2>,<&CLK_VOID>,<&CLK_VOID>,<&CLK_VOID>;
    reg = <REG_CKG_USB_PHYD_200_BASE 0x4>;
    mux-shift = <2>;  //2+REG_CKG_USB_PHYD_200_OFFSET
    mux-width = <2>;
    gate-shift = <0>;  //0+REG_CKG_USB_PHYD_200_OFFSET
    auto-enable = <0>;
};

CLK_disp_bt1120: CLK_disp_bt1120 {
    #clock-cells = <0>;
    compatible = "sstar,composite-clock";
    clocks = <&CLK_lpll_clk>,<&CLK_disppll_clk>,<&CLK_lpll_clk_div2>,<&CLK_lpll_clk_div4>,<&CLK_lpll_clk_div8>,<&CLK_disppll_clk_div2>,<&CLK_disppll_clk_div4>,<&CLK_disppll_clk_div8>;
    reg = <REG_CKG_DISP_BT1120_BASE 0x4>;
    mux-shift = <2>;  //2+REG_CKG_DISP_BT1120_OFFSET
    mux-width = <3>;
    gate-shift = <0>;  //0+REG_CKG_DISP_BT1120_OFFSET
    auto-enable = <0>;
};

CLK_bdma: CLK_bdma {
    #clock-cells = <0>;
    compatible = "sstar,composite-clock";
    clocks = <&CLK_riu_w_clk_in>,<&CLK_VOID>,<&CLK_VOID>,<&CLK_VOID>;
    reg = <REG_CKG_BDMA_BASE 0x4>;
    mux-shift = <2>;  //2+REG_CKG_BDMA_OFFSET
    mux-width = <2>;
    gate-shift = <0>;  //0+REG_CKG_BDMA_OFFSET
    auto-enable = <0>;
};

CLK_mcu_pm: CLK_mcu_pm {
    #clock-cells = <0>;
    compatible = "sstar,composite-clock";
    clocks = <&CLK_xtali_12m>,<&CLK_mpll_86m>,<&CLK_mpll_216m>,<&CLK_mpll_216m_div2>;
    reg = <REG_CKG_MCU_BASE 0x4>;
    mux-shift = <2>;  //2+REG_CKG_MCU_OFFSET
    mux-width = <2>;
    gate-shift = <0>;  //0+REG_CKG_MCU_OFFSET
    auto-enable = <1>;
};

CLK_spi_pm: CLK_spi_pm {
    #clock-cells = <0>;
    compatible = "sstar,composite-clock";
    clocks = <&CLK_xtali_24m>,<&CLK_SPI_SYNTH_CLK_OUT_buf>,<&CLK_mpll_86m>,<&CLK_mpll_216m_div2>,<&CLK_mpll_86m_div2>,<&CLK_mpll_216m_div4>,<&CLK_VOID>,<&CLK_VOID>;
    reg = <REG_CKG_SPI_BASE 0x4>;
    mux-shift = <10>;  //2+REG_CKG_SPI_OFFSET
    mux-width = <3>;
    gate-shift = <8>;  //0+REG_CKG_SPI_OFFSET
    glitch-shift = <14>;  //6+REG_CKG_SPI_OFFSET
    auto-enable = <1>;
};

CLK_pm_sleep: CLK_pm_sleep {
    #clock-cells = <0>;
    compatible = "sstar,composite-clock";
    clocks = <&CLK_xtali_12m>,<&CLK_rtc_32k>,<&CLK_xtali_12m_div8>,<&CLK_xtali_12m_div12>,<&CLK_rtc_32k_div4>,<&CLK_xtali_12m_div16>,<&CLK_xtali_12m_div2>,<&CLK_xtali_12m_div4>;
    reg = <REG_CKG_PM_SLEEP_BASE 0x4>;
    mux-shift = <12>;  //2+REG_CKG_PM_SLEEP_OFFSET
    mux-width = <3>;
    auto-enable = <0>;
};

CLK_sar: CLK_sar {
    #clock-cells = <0>;
    compatible = "sstar,composite-clock";
    clocks = <&CLK_xtali_12m>,<&CLK_rtc_32k>,<&CLK_VOID>,<&CLK_VOID>,<&CLK_VOID>,<&CLK_VOID>,<&CLK_VOID>,<&CLK_VOID>;
    reg = <REG_CKG_SAR_BASE 0x4>;
    mux-shift = <7>;  //2+REG_CKG_SAR_OFFSET
    mux-width = <3>;
    gate-shift = <5>;  //0+REG_CKG_SAR_OFFSET
    auto-enable = <0>;
};

CLK_rtc: CLK_rtc {
    #clock-cells = <0>;
    compatible = "sstar,composite-clock";
    clocks = <&CLK_xtali_12m>,<&CLK_rtc_32k>,<&CLK_VOID>,<&CLK_VOID>,<&CLK_VOID>,<&CLK_VOID>,<&CLK_VOID>,<&CLK_VOID>;
    reg = <REG_CKG_RTC_BASE 0x4>;
    mux-shift = <2>;  //2+REG_CKG_RTC_OFFSET
    mux-width = <3>;
    gate-shift = <0>;  //0+REG_CKG_RTC_OFFSET
    auto-enable = <0>;
};

CLK_ir: CLK_ir {
    #clock-cells = <0>;
    compatible = "sstar,composite-clock";
    clocks = <&CLK_xtali_24m>,<&CLK_xtali_12m>,<&CLK_xtali_12m_div2>,<&CLK_xtali_12m_div4>,<&CLK_xtali_12m_div8>,<&CLK_rtc_32k>,<&CLK_VOID>,<&CLK_VOID>;
    reg = <REG_CKG_IR_BASE 0x4>;
    mux-shift = <7>;  //2+REG_CKG_IR_OFFSET
    mux-width = <3>;
    gate-shift = <5>;  //0+REG_CKG_IR_OFFSET
    auto-enable = <0>;
};

/* for clock must be added by hand start */

CLK_bach: CLK_bach {
    #clock-cells = <0>;
    compatible = "sstar,composite-clock";
    clocks = <&CLK_upll_384m>;
    reg = <REG_CKG_BACH_384M_BASE 0x4>;
    gate-shift = <7>;  //0+REG_CKG_BACH_384M_OFFSET
    auto-enable = <0>;
};

/* for clock must be added by hand end */

#ifdef CONFIG_MS_USCLK
usclk: usclk {
    compatible = "usclk";
    clocks = <&CLK_RTC_CLK_32K>,
             <&CLK_SPI_SYNTH_CLK_OUT_buf>,
             <&CLK_VOID>,
             <&CLK_aesdma>,
             <&CLK_armpll_37p125m>,
             <&CLK_au_sys_384>,
             <&CLK_au_sys_432>,
             <&CLK_bdma>,
             <&CLK_bist>,
             <&CLK_bist_disp_gp>,
             <&CLK_bist_dsp_gp>,
             <&CLK_bist_ipu_gp>,
             <&CLK_bist_isp1_gp>,
             <&CLK_bist_isp_gp>,
             <&CLK_bist_mcu>,
             <&CLK_bist_miu0>,
             <&CLK_bist_miu1>,
             <&CLK_bist_net_gp>,
             <&CLK_bist_pcie0_gp>,
             <&CLK_bist_pcie1_gp>,
             <&CLK_bist_sata2_gp>,
             <&CLK_bist_sata_gp>,
             <&CLK_bist_sc_gp>,
             <&CLK_bist_usb30_drd_gp>,
             <&CLK_bist_vhe1_gp>,
             <&CLK_bist_vhe2_gp>,
             <&CLK_bist_vhe3_gp>,
             <&CLK_bist_vhe_gp>,
             <&CLK_cpu_pll>,
             <&CLK_cpupll_clk>,
             <&CLK_csi_mac_lptx_top_i_a0>,
             <&CLK_csi_mac_lptx_top_i_a1>,
             <&CLK_csi_mac_lptx_top_i_a2>,
             <&CLK_csi_mac_lptx_top_i_a3>,
             <&CLK_csi_mac_lptx_top_i_b0>,
             <&CLK_csi_mac_lptx_top_i_b1>,
             <&CLK_csi_mac_lptx_top_i_b2>,
             <&CLK_csi_mac_lptx_top_i_b3>,
             <&CLK_csi_mac_top_i_a0>,
             <&CLK_csi_mac_top_i_a1>,
             <&CLK_csi_mac_top_i_a2>,
             <&CLK_csi_mac_top_i_a3>,
             <&CLK_csi_mac_top_i_b0>,
             <&CLK_csi_mac_top_i_b1>,
             <&CLK_csi_mac_top_i_b2>,
             <&CLK_csi_mac_top_i_b3>,
             <&CLK_ddr_syn>,
             <&CLK_ddrpll_clk>,
             <&CLK_disp_216>,
             <&CLK_disp_432>,
             <&CLK_disp_bt1120>,
             <&CLK_disp_pixel_0>,
             <&CLK_disp_pixel_1>,
             <&CLK_disp_pixel_2>,
             <&CLK_disppll_clk>,
             <&CLK_disppll_clk_div2>,
             <&CLK_disppll_clk_div4>,
             <&CLK_disppll_clk_div8>,
             <&CLK_dsp>,
             <&CLK_dsppll_clk>,
             <&CLK_emac_testrx125_in_lan>,
             <&CLK_eth_buf>,
             <&CLK_fclk1>,
             <&CLK_fclk1_p>,
             <&CLK_fuart>,
             <&CLK_fuart0_synth_in>,
             <&CLK_fuart0_synth_out>,
             <&CLK_ge>,
             <&CLK_ge2>,
             <&CLK_gmac0_external_ref_buf>,
             <&CLK_gmac0_gmii>,
             <&CLK_gmac1_external_ref_buf>,
             <&CLK_gmac1_gmii>,
             <&CLK_gmacpll_250>,
             <&CLK_gmacpll_250_div10>,
             <&CLK_gmacpll_250_div100>,
             <&CLK_gmacpll_250_div2>,
             <&CLK_gmacpll_250_div5>,
             <&CLK_ipu>,
             <&CLK_ipuff>,
             <&CLK_ipupll_clk>,
             <&CLK_ir>,
             <&CLK_isp>,
             <&CLK_isp1>,
             <&CLK_isp_p>,
             <&CLK_isppll_clk>,
             <&CLK_isppll_clk_div16>,
             <&CLK_isppll_clk_div2>,
             <&CLK_isppll_clk_div4>,
             <&CLK_isppll_clk_div8>,
             <&CLK_ive>,
             <&CLK_jpd>,
             <&CLK_jpd1>,
             <&CLK_jpd2>,
             <&CLK_jpd3>,
             <&CLK_jpe>,
             <&CLK_jpe1>,
             <&CLK_ldcfeye>,
             <&CLK_ldcfeye2>,
             <&CLK_live>,
             <&CLK_live_c>,
             <&CLK_live_pm>,
             <&CLK_lpll_clk>,
             <&CLK_lpll_clk_div2>,
             <&CLK_lpll_clk_div4>,
             <&CLK_lpll_clk_div8>,
             <&CLK_lvds_func_a0>,
             <&CLK_lvds_func_a1>,
             <&CLK_lvds_func_a2>,
             <&CLK_lvds_func_a3>,
             <&CLK_lvds_func_a4>,
             <&CLK_lvds_func_a5>,
             <&CLK_lvds_func_a6>,
             <&CLK_lvds_func_a7>,
             <&CLK_mcu>,
             <&CLK_mcu_p>,
             <&CLK_mcu_pm>,
             <&CLK_mcu_pm_p>,
             <&CLK_mfe>,
             <&CLK_mfe1>,
             <&CLK_mfe2>,
             <&CLK_mfe3>,
             <&CLK_miic0>,
             <&CLK_miic1>,
             <&CLK_miic10>,
             <&CLK_miic2>,
             <&CLK_miic3>,
             <&CLK_miic4>,
             <&CLK_miic5>,
             <&CLK_miic6>,
             <&CLK_miic7>,
             <&CLK_miic8>,
             <&CLK_miic9>,
             <&CLK_mipi_tx_csi>,
             <&CLK_mipi_tx_dsi>,
             <&CLK_miu>,
             <&CLK_miu2x_p>,
             <&CLK_miu_isp_gp_p>,
             <&CLK_miu_p>,
             <&CLK_miu_rec>,
             <&CLK_miu_sc_gp_p>,
             <&CLK_miu_vhe_gp_p>,
             <&CLK_miupll_clk>,
             <&CLK_mop0>,
             <&CLK_mop1>,
             <&CLK_mop2>,
             <&CLK_mpll_123m>,
             <&CLK_mpll_123m_div2>,
             <&CLK_mpll_144m>,
             <&CLK_mpll_144m_div2>,
             <&CLK_mpll_144m_div4>,
             <&CLK_mpll_172m>,
             <&CLK_mpll_216m>,
             <&CLK_mpll_216m_div2>,
             <&CLK_mpll_216m_div4>,
             <&CLK_mpll_216m_div8>,
             <&CLK_mpll_246m>,
             <&CLK_mpll_246m_div2>,
             <&CLK_mpll_246m_div4>,
             <&CLK_mpll_288m>,
             <&CLK_mpll_288m_div2>,
             <&CLK_mpll_288m_div4>,
             <&CLK_mpll_288m_div8>,
             <&CLK_mpll_345m>,
             <&CLK_mpll_345m_div2>,
             <&CLK_mpll_432m>,
             <&CLK_mpll_432m_div16>,
             <&CLK_mpll_432m_div2>,
             <&CLK_mpll_432m_div4>,
             <&CLK_mpll_432m_div8>,
             <&CLK_mpll_576m>,
             <&CLK_mpll_691m>,
             <&CLK_mpll_86m>,
             <&CLK_mpll_86m_div16>,
             <&CLK_mpll_86m_div2>,
             <&CLK_mpll_86m_div4>,
             <&CLK_mspi0>,
             <&CLK_mspi0_p>,
             <&CLK_mspi1>,
             <&CLK_mspi1_p>,
             <&CLK_mspi2>,
             <&CLK_mspi3>,
             <&CLK_ns_top_i_a0>,
             <&CLK_ns_top_i_a1>,
             <&CLK_ns_top_i_a2>,
             <&CLK_ns_top_i_a3>,
             <&CLK_ns_top_i_b0>,
             <&CLK_ns_top_i_b1>,
             <&CLK_ns_top_i_b2>,
             <&CLK_ns_top_i_b3>,
             <&CLK_pcie0>,
             <&CLK_pcie0_bs>,
             <&CLK_pcie0_jtg>,
             <&CLK_pcie0_ref_alt>,
             <&CLK_pcie0_slv_aclk>,
             <&CLK_pcie1>,
             <&CLK_pcie1_bs>,
             <&CLK_pcie1_jtg>,
             <&CLK_pcie1_ref_alt>,
             <&CLK_pcie1_slv_aclk>,
             <&CLK_pm_riu_w_clk_in>,
             <&CLK_pm_sleep>,
             <&CLK_pwm>,
             <&CLK_pwr_ctl>,
             <&CLK_riu_pm>,
             <&CLK_riu_w_clk_hemcu_gp>,
             <&CLK_riu_w_clk_in>,
             <&CLK_riu_w_clk_mcu_if_gp>,
             <&CLK_riu_w_clk_mipi_if_gp>,
             <&CLK_riu_w_clk_sc_gp>,
             <&CLK_riu_w_clk_top>,
             <&CLK_riu_w_clk_vhe_gp>,
             <&CLK_riubrdg>,
             <&CLK_rmii_buf>,
             <&CLK_rtc>,
             <&CLK_rtc_32k>,
             <&CLK_rtc_32k_div4>,
             <&CLK_sar>,
             <&CLK_sata2_phy_108>,
             <&CLK_sata2_phy_432>,
             <&CLK_sata2_pm>,
             <&CLK_sata_phy_108>,
             <&CLK_sata_phy_432>,
             <&CLK_sata_pm>,
             <&CLK_sd>,
             <&CLK_sd_1x_p>,
             <&CLK_sd_2x_p>,
             <&CLK_sd_syn>,
             <&CLK_sdio>,
             <&CLK_sdio2>,
             <&CLK_sdio3>,
             <&CLK_sdio_p>,
             <&CLK_sof_usb30_drd>,
             <&CLK_spi_arb>,
             <&CLK_spi_pm>,
             <&CLK_spi_synth_pll>,
             <&CLK_spipll_clk>,
             <&CLK_sr00_mclk>,
             <&CLK_sr01_mclk>,
             <&CLK_sr02_mclk>,
             <&CLK_sr03_mclk>,
             <&CLK_sr10_mclk>,
             <&CLK_sr11_mclk>,
             <&CLK_sr12_mclk>,
             <&CLK_sr13_mclk>,
             <&CLK_sr_mclk>,
             <&CLK_ssm0>,
             <&CLK_ssm1>,
             <&CLK_ssusb_phy_108>,
             <&CLK_ssusb_phy_432>,
             <&CLK_syspll_400m>,
             <&CLK_syspll_400m_div2>,
             <&CLK_syspll_400m_div4>,
             <&CLK_syspll_400m_div8>,
             <&CLK_syspll_600m>,
             <&CLK_syspll_clk>,
             <&CLK_tck_buf>,
             <&CLK_uart0>,
             <&CLK_uart1>,
             <&CLK_uart2>,
             <&CLK_uart3>,
             <&CLK_uart4>,
             <&CLK_uart5>,
             <&CLK_upll_320m>,
             <&CLK_upll_320m_div10>,
             <&CLK_upll_320m_div16>,
             <&CLK_upll_320m_div2>,
             <&CLK_upll_320m_div8>,
             <&CLK_upll_384m>,
             <&CLK_upll_384m_div2>,
             <&CLK_upll_384m_div8>,
             <&CLK_upll_480m>,
             <&CLK_upll_480m_div2>,
             <&CLK_usb_phyd_200>,
             <&CLK_utmi>,
             <&CLK_utmi_160m>,
             <&CLK_utmi_160m_div4>,
             <&CLK_utmi_160m_div5>,
             <&CLK_utmi_160m_div8>,
             <&CLK_utmi_192m>,
             <&CLK_utmi_192m_div4>,
             <&CLK_utmi_240m>,
             <&CLK_ven1_axi>,
             <&CLK_ven2_axi>,
             <&CLK_ven3_axi>,
             <&CLK_ven_axi>,
             <&CLK_ven_pll>,
             <&CLK_ven_pll_div6>,
             <&CLK_vhe>,
             <&CLK_vhe1>,
             <&CLK_vhe2>,
             <&CLK_vhe3>,
             <&CLK_xtali>,
             <&CLK_xtali_12m>,
             <&CLK_xtali_12m_div12>,
             <&CLK_xtali_12m_div128>,
             <&CLK_xtali_12m_div16>,
             <&CLK_xtali_12m_div2>,
             <&CLK_xtali_12m_div4>,
             <&CLK_xtali_12m_div40>,
             <&CLK_xtali_12m_div64>,
             <&CLK_xtali_12m_div8>,
             <&CLK_xtali_24m>,
             <&CLK_xtali_sc_gp>;
/* for clock must be added by hand start */
             <&CLK_bach>;
/* for clock must be added by hand end */
    clock-count = <305>;
};
#endif
